[part 1 of 2: package /ComponentTypes]
AUTOSAR XML (schema 00050)
package /ComponentTypes
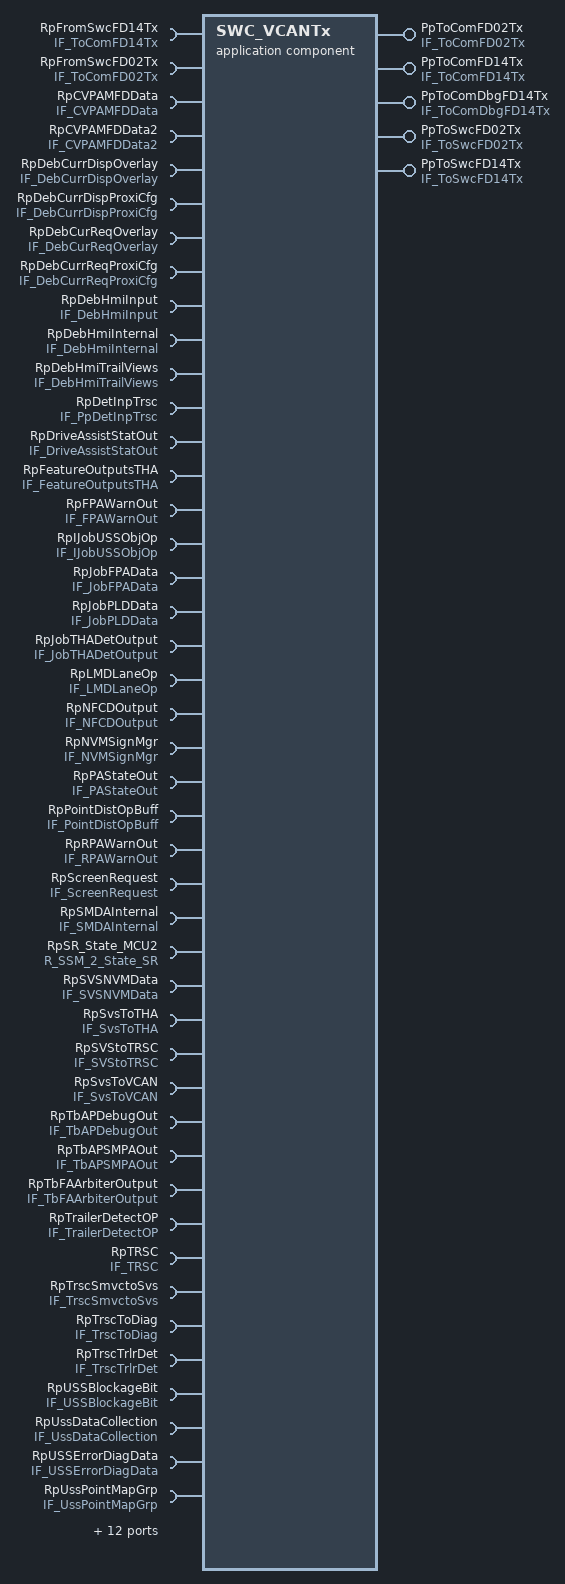
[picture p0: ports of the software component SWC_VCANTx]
  application sw component type SWC_VCANTx
    provide port PpToComFD02Tx: provided-interface=IF_ToComFD02Tx
      provided-com-specs:
        data-element=CurrentCanNMState_FD02_PAM, init-value=0
        data-element=CurrentFailSts_FD02_PAM, init-value=0
        data-element=DES_FD02_PAM, init-value=0
        data-element=Digit_{01..11}_PAM, init-value=0
        data-element=EOL_FD02_PAM, init-value=0
        data-element=GenericFailSts_FD02_PAM, init-value=0
        {data-element=N_PDU, init-value=[rule-based-values={rule=FILL_UNTIL_END, rule-arguments=0}]}
        data-element=PreviousCanNMState_FD02_PAM, init-value=0
        {data-element=StayActiveSource_FD02_PAM, init-value=[rule-based-values={rule=FILL_UNTIL_END, rule-arguments=0}]}
        data-element=THA_EPB_Req, init-value=0
        data-element=THA_Speed_Limit, init-value=0
        data-element=THA_SpeedLimit_Req, init-value=0
        data-element=THA_STAT, init-value=0
        data-element=THA_SteeringDamping, init-value=78.125
        data-element=THA_SteeringTorqueInfo, init-value=0
        data-element=THA_SteeringTorqueReq, init-value=0
        data-element=Trailer_Angle, init-value=0
        data-element=Trailer_Angle_Sign, init-value=0
        data-element=Trailer_Calibration, init-value=0
        data-element=TrlrHitchLight_Cntrl, init-value=0
        data-element=TRSC_PopupDisp_Info, init-value=0
        data-element=TRSC_SpeedLimit_Req, init-value=0
        data-element=TRSC_STAT, init-value=1
        data-element=TRSC_SteeringDamping, init-value=100
        data-element=TRSC_SteeringTorqueInfo, init-value=0
        data-element=TRSC_SteeringTorqueReq, init-value=0
        data-element=TRSC_VehicleStop_Req, init-value=3
        data-element=TRSCMoreCamRQSts, init-value=0
        data-element=WakeupSource_FD02_PAM, init-value=0
        data-element=TRSC_PopupDisp_Info2, init-value=0
    provide port PpToComFD14Tx: provided-interface=IF_ToComFD14Tx
      provided-com-specs:
        data-element=FD14_THA_EPB_Req, init-value=0
        data-element=FD14_THA_Speed_Limit, init-value=0
        data-element=FD14_THA_SpeedLimit_Req, init-value=0
        data-element=FD14_THA_STAT, init-value=0
        data-element=FD14_THA_SteeringDamping, init-value=100
        data-element=FD14_THA_SteeringTorqueInfo, init-value=1024
        data-element=FD14_THA_SteeringTorqueReq, init-value=0
        data-element=FD14_TRSC_SpeedLimit_Req, init-value=0
        data-element=FD14_TRSC_STAT, init-value=1
        data-element=FD14_TRSC_SteeringDamping, init-value=100
        data-element=FD14_TRSC_SteeringTorqueInfo, init-value=1024
        data-element=FD14_TRSC_SteeringTorqueReq, init-value=0
        data-element=FD14_TRSC_VehicleStop_Req, init-value=3
    require port RpFromSwcFD14Tx: required-interface=IF_ToComFD14Tx
      required-com-specs:
        data-element=FD14_THA_EPB_Req, filter=data-filter-type=ALWAYS, init-value=0
        data-element=FD14_THA_Speed_Limit, filter=data-filter-type=ALWAYS, init-value=0
        data-element=FD14_THA_SpeedLimit_Req, filter=data-filter-type=ALWAYS, init-value=0
        data-element=FD14_THA_STAT, filter=data-filter-type=ALWAYS, init-value=0
        data-element=FD14_THA_SteeringDamping, filter=data-filter-type=ALWAYS, init-value=100
        data-element=FD14_THA_SteeringTorqueInfo, filter=data-filter-type=ALWAYS, init-value=1024
        data-element=FD14_THA_SteeringTorqueReq, filter=data-filter-type=ALWAYS, init-value=0
        data-element=FD14_TRSC_SpeedLimit_Req, filter=data-filter-type=ALWAYS, init-value=0
        data-element=FD14_TRSC_STAT, filter=data-filter-type=ALWAYS, init-value=1
        data-element=FD14_TRSC_SteeringDamping, filter=data-filter-type=ALWAYS, init-value=100
        data-element=FD14_TRSC_SteeringTorqueInfo, filter=data-filter-type=ALWAYS, init-value=1024
        data-element=FD14_TRSC_SteeringTorqueReq, filter=data-filter-type=ALWAYS, init-value=0
        data-element=FD14_TRSC_VehicleStop_Req, filter=data-filter-type=ALWAYS, init-value=3
    provide port PpToComDbgFD14Tx: provided-interface=IF_ToComDbgFD14Tx
      provided-com-specs:
        data-element=FD14_MeTRSC_cnt_TRSCAliveCounter, init-value=0
        data-element=FD14_MeTRSC_deg_TADAngleSMVC, init-value=0
        data-element=FD14_MeTRSC_e_TrlrCalInfoSMVC, init-value=0
        data-element=FD14_MeTRSC_s_TRSCPeriodicity, init-value=0
        data-element=FD14_MeTRSC_s_TRSCTimeTaken, init-value=0
        data-element=FD14_ReservedSignal1, init-value=0
        data-element=FD14_ReservedSignal2, init-value=0
        data-element=FD14_ReservedTRSCSig1, init-value=0
        data-element=FD14_ReservedTRSCSig2, init-value=0
        data-element=FD14_averageIllumination, init-value=0
        data-element=FD14_CsmLocalErrOrEventId, init-value=0
        data-element=FD14_CsmLocalErrOrEventState, init-value=7
        data-element=FD14_CsmLocalModuleId, init-value=15
        data-element=FD14_CsmLocalModuleInstanceId, init-value=0
        data-element=FD14_CsmStateCurrent, init-value=15
        data-element=FD14_CsmStatePrevious, init-value=15
        data-element=FD14_hitchCalibrationAngle, init-value=0
        data-element=FD14_leftCalibrationAngle, init-value=0
        data-element=FD14_MeTRSC_b_OTBLReset, init-value=0
        data-element=FD14_MeTRSC_b_TBLComputationDone, init-value=0
        data-element=FD14_MeTRSC_deg_StrCMD, init-value=0
        data-element=FD14_rightCalibrationAngle, init-value=0
        data-element=FD14__JackKnifeAngle, init-value=0
        data-element=FD14_AOL_Blockage, init-value=0
        data-element=FD14_AOL_comm_Fault, init-value=0
        data-element=FD14_AOL_CommUnknown, init-value=0
        data-element=FD14_AOL_hardware_Fault, init-value=0
        data-element=FD14_AOL_MinDistance, init-value=0
        data-element=FD14_AOL_overTemp_Fault, init-value=0
        data-element=FD14_AOR_Blockage, init-value=0
        data-element=FD14_AOR_comm_Fault, init-value=0
        data-element=FD14_AOR_CommUnknown, init-value=0
        data-element=FD14_AOR_hardware_Fault, init-value=0
        data-element=FD14_AOR_MinDistance, init-value=0
        data-element=FD14_AOR_overTemp_Fault, init-value=0
        data-element=FD14_AutoParkInitializedStatus_b, init-value=0
        data-element=FD14_AuxCamButton1NoSelect_b, init-value=0
        data-element=FD14_AuxCamButton1Select_b, init-value=0
        data-element=FD14_AuxCamButton2NoSelect_b, init-value=0
        data-element=FD14_AuxCamButton2Select_b, init-value=0
        data-element=FD14_BackCam_NA_b, init-value=0
        data-element=FD14_BackDoorOpen_Icon_b, init-value=0
        data-element=FD14_BackupRearCamButtonNoSelect_b, init-value=0
        data-element=FD14_BackupRearCamButtonSelect_b, init-value=0
        data-element=FD14_BOL_Blockage, init-value=0
        data-element=FD14_BOL_comm_Fault, init-value=0
        data-element=FD14_BOL_CommUnknown, init-value=0
        data-element=FD14_BOL_hardware_Fault, init-value=0
        data-element=FD14_BOL_MinDistance, init-value=0
        data-element=FD14_BOL_overTemp_Fault, init-value=0
        data-element=FD14_BOR_Blockage, init-value=0
        data-element=FD14_BOR_comm_Fault, init-value=0
        data-element=FD14_BOR_CommUnknown, init-value=0
        data-element=FD14_BOR_hardware_Fault, init-value=0
        data-element=FD14_BOR_MinDistance, init-value=0
        data-element=FD14_BOR_overTemp_Fault, init-value=0
        data-element=FD14_BumberStatus_Front, init-value=0
        data-element=FD14_BumberStatus_Left_Side, init-value=0
        data-element=FD14_BumberStatus_Rear, init-value=0
        data-element=FD14_BumberStatus_Right_Side, init-value=0
        data-element=FD14_calibrationCompleted, init-value=0
        data-element=FD14_calibrationSubState, init-value=0
        data-element=FD14_CalibStatus_STM_Current_Front, init-value=0
        data-element=FD14_CalibStatus_STM_Current_Left, init-value=0
        data-element=FD14_CalibStatus_STM_Current_Rear, init-value=0
        data-element=FD14_CalibStatus_STM_Current_Right, init-value=0
        data-element=FD14_CalibStatus_STM_EOL_Front, init-value=0
        data-element=FD14_CalibStatus_STM_EOL_Left, init-value=0
        data-element=FD14_CalibStatus_STM_EOL_Rear, init-value=0
        data-element=FD14_CalibStatus_STM_EOL_Right, init-value=0
        data-element=FD14_CalibStatus_STM_OC_Front, init-value=0
        data-element=FD14_CalibStatus_STM_OC_Left, init-value=0
        data-element=FD14_CalibStatus_STM_OC_Rear, init-value=0
        data-element=FD14_CalibStatus_STM_OC_Right, init-value=0
        data-element=FD14_CalibStatus_STM_SC_Front, init-value=0
        data-element=FD14_CalibStatus_STM_SC_Left, init-value=0
        data-element=FD14_CalibStatus_STM_SC_Rear, init-value=0
        data-element=FD14_CalibStatus_STM_SC_Right, init-value=0
        data-element=FD14_CAM_NA_Bitfield_u8, init-value=0
        data-element=FD14_CameraDisplaySts2_e, init-value=0
        data-element=FD14_cntrCvpamFdData1_u16, init-value=0
        data-element=FD14_crcCvpamFdData1_u8, init-value=0
        data-element=FD14_Curr_DisplayedViewByAcore_e, init-value=0
        data-element=FD14_Curr_RequestedViewByHmiM_e, init-value=0
        data-element=FD14_Curr_SystemState_e, init-value=0
        data-element=FD14_Curr_TRG_Stat, init-value=0
        data-element=FD14_Current_Firing_Sequence, init-value=0
        data-element=FD14_CurrentTrailer_ID, init-value=6
        data-element=FD14_curState, init-value=0
        data-element=FD14_Debug_Signal_{1..8}, init-value=0
        data-element=FD14_DynOvl_Error_e, init-value=0
        data-element=FD14_EOL_ModuleState_STM_Front, init-value=0
        data-element=FD14_EOL_ModuleState_STM_Left, init-value=0
        data-element=FD14_EOL_ModuleState_STM_Rear, init-value=0
        data-element=FD14_EOL_ModuleState_STM_Right, init-value=0
        data-element=FD14_Err_Code_EOL_Front, init-value=0
        data-element=FD14_Err_Code_EOL_Left, init-value=0
        data-element=FD14_Err_Code_EOL_Rear, init-value=0
        data-element=FD14_Err_Code_EOL_Rear_Copy_1, init-value=0
        data-element=FD14_Err_Code_OC_Front, init-value=0
        data-element=FD14_Err_Code_OC_Left, init-value=0
        data-element=FD14_Err_Code_OC_Rear, init-value=0
        data-element=FD14_Err_Code_OC_Right, init-value=0
        data-element=FD14_Err_Code_SC_Front, init-value=0
        data-element=FD14_Err_Code_SC_Left, init-value=0
        data-element=FD14_Err_Code_SC_Rear, init-value=0
        data-element=FD14_Err_Code_SC_Right, init-value=0
        data-element=FD14_FFCV_BTN_PRESSED_b, init-value=0
        data-element=FD14_FIL_Blockage, init-value=0
        data-element=FD14_FIL_comm_Fault, init-value=0
        data-element=FD14_FIL_CommUnknown, init-value=0
        data-element=FD14_FIL_hardware_Fault, init-value=0
        data-element=FD14_FIL_MinDistance, init-value=0
        data-element=FD14_FIL_overTemp_Fault, init-value=0
        data-element=FD14_FIR_Blockage, init-value=0
        data-element=FD14_FIR_comm_Fault, init-value=0
        data-element=FD14_FIR_CommUnknown, init-value=0
        data-element=FD14_FIR_hardware_Fault, init-value=0
        data-element=FD14_FIR_MinDistance, init-value=0
        data-element=FD14_FIR_overTemp_Fault, init-value=0
        data-element=FD14_Firing_Mode_Seq, init-value=0
        data-element=FD14_Firing_Sensor, init-value=0
        data-element=FD14_Firing_Sensor_Info_F, init-value=0
        data-element=FD14_Firing_Sensor_Info_R, init-value=0
        data-element=FD14_FiringMode_TimeStamp, init-value=0
        data-element=FD14_FiringSnr_TimeStamp, init-value=0
        data-element=FD14_FOL_Blockage, init-value=0
        data-element=FD14_FOL_comm_Fault, init-value=0
        data-element=FD14_FOL_CommUnknown, init-value=0
        data-element=FD14_FOL_hardware_Fault, init-value=0
        data-element=FD14_FOL_MinDistance, init-value=0
        data-element=FD14_FOL_overTemp_Fault, init-value=0
        data-element=FD14_FOR_Blockage, init-value=0
        data-element=FD14_FOR_comm_Fault, init-value=0
        data-element=FD14_FOR_CommUnknown, init-value=0
        data-element=FD14_FOR_hardware_Fault, init-value=0
        data-element=FD14_FOR_MinDistance, init-value=0
        data-element=FD14_FOR_overTemp_Fault, init-value=0
        data-element=FD14_Frame_Index_Lanes__1, init-value=0
        data-element=FD14_Frameset1AndTopFrontText_b, init-value=0
        data-element=FD14_Frameset1AndTopRearText_b, init-value=0
        data-element=FD14_Frameset2AndFrontCrossText_b, init-value=0
        data-element=FD14_Frameset2AndRearCrossText_b, init-value=0
        data-element=FD14_FRONT_CROSS_BTN_PRESSED_b, init-value=0
        data-element=FD14_FRONT_TOP_BTN_PRESSED_b, init-value=0
        data-element=FD14_FrontCam_NA_b, init-value=0
        data-element=FD14_FrontCrossButtonNoSelect_b, init-value=0
        data-element=FD14_FrontCrossButtonSelect_b, init-value=0
        data-element=FD14_FrontFaceCamButtonNoSelect_b, init-value=0
        data-element=FD14_FrontFaceCamButtonSelect_b, init-value=0
        data-element=FD14_FrontSensorDetHealth_e, init-value=0
        data-element=FD14_FrontTireTracks_b, init-value=0
        data-element=FD14_FrontViewDynamics_b, init-value=0
        data-element=FD14_FSL_Blockage, init-value=0
        data-element=FD14_FSL_comm_Fault, init-value=0
        data-element=FD14_FSL_CommUnknown, init-value=0
        data-element=FD14_FSL_hardware_Fault, init-value=0
        data-element=FD14_FSL_MinDistance, init-value=0
        data-element=FD14_FSL_overTemp_Fault, init-value=0
        data-element=FD14_FSR_Blockage, init-value=0
        data-element=FD14_FSR_comm_Fault, init-value=0
        data-element=FD14_FSR_CommUnknown, init-value=0
        data-element=FD14_FSR_hardware_Fault, init-value=0
        data-element=FD14_FSR_MinDistance, init-value=0
        data-element=FD14_FSR_overTemp_Fault, init-value=0
        data-element=FD14_GW_C_I6_timeout_b, init-value=1
        data-element=FD14_hitchLength, init-value=100000
        data-element=FD14_IeAP_b_MnvPosOk, init-value=0
        data-element=FD14_IeAP_cm_FrntCenterMinXDist, init-value=0
        data-element=FD14_IeAP_cm_FrntCenterMinXDist_KPI, init-value=0
        data-element=FD14_IeAP_cm_FrntLeftMinXDist, init-value=0
        data-element=FD14_IeAP_cm_FrntLeftMinXDist_KPI, init-value=0
        data-element=FD14_IeAP_cm_FrntRightMinXDist, init-value=0
        data-element=FD14_IeAP_cm_FrntRightMinXDist_KPI, init-value=0
        data-element=FD14_IeAP_cm_RearCenterMinXDist, init-value=0
        data-element=FD14_IeAP_cm_RearCenterMinXDist_KPI, init-value=0
        data-element=FD14_IeAP_cm_RearLeftMinXDist, init-value=0
        data-element=FD14_IeAP_cm_RearLeftMinXDist_KPI, init-value=0
        data-element=FD14_IeAP_cm_RearRightMinXDist, init-value=0
        data-element=FD14_IeAP_cm_RearRightMinXDist_KPI, init-value=0
        data-element=FD14_IeAP_cnt_CurrentVehSweep, init-value=0
        data-element=FD14_IeAP_e_AbortCon, init-value=0
        data-element=FD14_IeAP_e_AutoParkStatus, init-value=0
        data-element=FD14_IeAutoPark_e_AlgoState, init-value=0
        data-element=FD14_IeLMD_e_CameraStatus, init-value=0
        data-element=FD14_IeTHA_b_ChimeActvLhf, init-value=0
        data-element=FD14_IeTHA_b_ChimeActvRhf, init-value=0
        data-element=FD14_IeTHA_e_PamChimeTyp, init-value=0
        data-element=FD14_IeTHA_e_PamVol, init-value=0
        data-element=FD14_IeTRSC_cnt_KnobPos, init-value=0
        data-element=FD14_IeTRSC_cnt_TrlrCalibFailCnt, init-value=0
        data-element=FD14_IeTRSC_cnt_TrlrCalibFailCntCurr, init-value=0
        data-element=FD14_IeTRSC_cnt_TrlrCalibPassCnt, init-value=0
        data-element=FD14_IeTRSC_cnt_TrlrCalibPassCntCurr, init-value=0
        data-element=FD14_IeTRSC_deg_FrntWhlAng, init-value=0
        data-element=FD14_IeTRSC_deg_JackknifeThrAngle, init-value=0
        data-element=FD14_IeTRSC_deg_TADAngle, init-value=0
        data-element=FD14_IeTRSC_deg_TrlrAngKnob, init-value=0
        data-element=FD14_IeTRSC_e_CamBlockSts, init-value=0
        data-element=FD14_IeTRSC_e_GearShiftSts, init-value=0
        data-element=FD14_IeTRSC_e_TrailerID, init-value=0
        data-element=FD14_IeTRSC_e_TrlrAngGrapOverSts, init-value=0
        data-element=FD14_IeTRSC_e_TrlrCalibFailReas, init-value=0
        data-element=FD14_IeTRSC_e_TrlrCalibManState, init-value=0
        data-element=FD14_IeTRSC_e_TrlrCalibSts, init-value=0
        data-element=FD14_IeTRSC_e_TrlrPrsntFailReas, init-value=0
        data-element=FD14_IeTRSC_e_TrlrPrsntSts, init-value=0
        data-element=FD14_IeTRSC_e_TrlrRecogInfo, init-value=0
        data-element=FD14_IeTRSC_e_TRSCAbortReas, init-value=0
        data-element=FD14_IeTRSC_e_TRSCUnavailReas, init-value=0
        data-element=FD14_IeTRSC_e_TRSKMBtnSts, init-value=0
        data-element=FD14_IeTRSC_e_TRSKMCenBtnSts, init-value=0
        data-element=FD14_IeTRSC_e_TRSKMSts, init-value=0
        data-element=FD14_IeTRSC_kph_VehSpeedVSOSig, init-value=0
        data-element=FD14_IeTRSC_m_TrlrWhlBaseEff, init-value=0
        data-element=FD14_IeTRSC_M_TRSCStrTrq, init-value=0
        data-element=FD14_IeTRSC_pct_TrlrDetConf, init-value=0
        data-element=FD14_IeTRSC_pct_TrlrRecogConf, init-value=0
        data-element=FD14_IeTRSC_pct_TrlrTrackConf, init-value=0
        data-element=FD14_IeVBII_nfcd_MinDisToCollisionObj, init-value=0
        data-element=FD14_ignitionStatus_e, init-value=0
        data-element=FD14_IgnoredFeatures_Front_u32, init-value=0
        data-element=FD14_IgnoredFeatures_Left_u32, init-value=0
        data-element=FD14_IgnoredFeatures_Rear_u32, init-value=0
        data-element=FD14_IgnoredFeatures_Right_u32, init-value=0
        data-element=FD14_IgnoreVehicleOffSpeed, init-value=0
        data-element=FD14_ImageDefeat_Error_e, init-value=0
        data-element=FD14_InvalidFeatures_Front_u32, init-value=0
        data-element=FD14_InvalidFeatures_Left_u32, init-value=0
        data-element=FD14_InvalidFeatures_Rear_u32, init-value=0
        data-element=FD14_InvalidFeatures_Right_u32, init-value=0
        data-element=FD14_IsBackSftbtnSel, init-value=0
        data-element=FD14_IsExitSftBtnSel, init-value=0
        data-element=FD14_IsParkSftBtnSel, init-value=0
        data-element=FD14_isPLDInitSuccess_b, init-value=0
        data-element=FD14_IsSlotSel, init-value=0
        data-element=FD14_isUSSInitSuccess_b, init-value=0
        data-element=FD14_ItbmTrailerStatus, init-value=0
        data-element=FD14_JackknifeAngle, init-value=0
        data-element=FD14_JackknifeThrAngle, init-value=0
        data-element=FD14_KnobAngle, init-value=0
        data-element=FD14_LanguageSelection_u8, init-value=0
        data-element=FD14_LastViewBeforeTestPattern_e, init-value=0
        data-element=FD14_LeftCam_NA_b, init-value=0
        data-element=FD14_LeftDoorFrontClose_Icon_b, init-value=0
        data-element=FD14_LeftDoorFrontOpen_Icon_b, init-value=0
        data-element=FD14_LeftDoorRearClose_Icon_b, init-value=0
        data-element=FD14_LeftDoorRearOpen_Icon_b, init-value=0
        data-element=FD14_leLMD_e_HealthStatus, init-value=0
        data-element=FD14_LMD_e_Line_{1..4}_Type, init-value=0
        data-element=FD14_LMD_e_Segment_{1..8}_ID, init-value=0
        data-element=FD14_LMD_m_Line_1_End_Range, init-value=0
        data-element=FD14_LMD_m_Line_1_Offset, init-value=0
        data-element=FD14_LMD_m_Line_1_Start_Range, init-value=0
        data-element=FD14_LMD_m_Line_2_End_Range, init-value=0
        data-element=FD14_LMD_m_Line_2_Offset, init-value=0
        data-element=FD14_LMD_m_Line_2_Start_Range, init-value=0
        data-element=FD14_LMD_m_Line_3_End_Range, init-value=0
        data-element=FD14_LMD_m_Line_3_Offset, init-value=0
        data-element=FD14_LMD_m_Line_3_Start_Range, init-value=0
        data-element=FD14_LMD_m_Line_4_End_Range, init-value=0
        data-element=FD14_LMD_m_Line_4_Offset, init-value=0
        data-element=FD14_LMD_m_Line_4_Start_Range, init-value=0
        data-element=FD14_LMD_m_Segment_1_X1, init-value=0
        data-element=FD14_LMD_m_Segment_1_X2, init-value=0
        data-element=FD14_LMD_m_Segment_1_Y1, init-value=0
        data-element=FD14_LMD_m_Segment_1_Y2, init-value=0
        data-element=FD14_LMD_m_Segment_2_X1, init-value=0
        data-element=FD14_LMD_m_Segment_2_X2, init-value=0
        data-element=FD14_LMD_m_Segment_2_Y1, init-value=0
        data-element=FD14_LMD_m_Segment_2_Y2, init-value=0
        data-element=FD14_LMD_m_Segment_3_X1, init-value=0
        data-element=FD14_LMD_m_Segment_3_X2, init-value=0
        data-element=FD14_LMD_m_Segment_3_Y1, init-value=0
        data-element=FD14_LMD_m_Segment_3_Y2, init-value=0
        data-element=FD14_LMD_m_Segment_4_X1, init-value=0
        data-element=FD14_LMD_m_Segment_4_X2, init-value=0
        data-element=FD14_LMD_m_Segment_4_Y1, init-value=0
        data-element=FD14_LMD_m_Segment_4_Y2, init-value=0
        data-element=FD14_LMD_m_Segment_5_X1, init-value=0
        data-element=FD14_LMD_m_Segment_5_X2, init-value=0
        data-element=FD14_LMD_m_Segment_5_Y1, init-value=0
        data-element=FD14_LMD_m_Segment_5_Y2, init-value=0
        data-element=FD14_LMD_m_Segment_6_X1, init-value=0
        data-element=FD14_LMD_m_Segment_6_X2, init-value=0
        data-element=FD14_LMD_m_Segment_6_Y1, init-value=0
        data-element=FD14_LMD_m_Segment_6_Y2, init-value=0
        data-element=FD14_LMD_m_Segment_7_X1, init-value=0
        data-element=FD14_LMD_m_Segment_7_X2, init-value=0
        data-element=FD14_LMD_m_Segment_7_Y1, init-value=0
        data-element=FD14_LMD_m_Segment_7_Y2, init-value=0
        data-element=FD14_LMD_m_Segment_8_X1, init-value=0
        data-element=FD14_LMD_m_Segment_8_X2, init-value=0
        data-element=FD14_LMD_m_Segment_8_Y1, init-value=0
        data-element=FD14_LMD_m_Segment_8_Y2, init-value=0
        data-element=FD14_LMD_pct_Line_{1..4}_Confidence, init-value=0
        data-element=FD14_LMD_pct_Segment_{1..8}_Confidence, init-value=0
        data-element=FD14_LMD_px_Line_{1..4}_Curvature, init-value=0
        data-element=FD14_LMD_rad_Line_{1..4}_Heading, init-value=0
        {data-element=FD14_Log_Sensor_Temperature, init-value=[rule-based-values={rule=FILL_UNTIL_END, rule-arguments=0}]}
        {data-element=FD14_Log_SnrMeasData_{1..7}, init-value=[rule-based-values={rule=FILL_UNTIL_END, rule-arguments=0}]}
        data-element=FD14_lrwsST_e, init-value=0
        data-element=FD14_M_BURV_Memory_e, init-value=0
        data-element=FD14_M_CONFIRM_BTN_PRESSED_b, init-value=0
        data-element=FD14_M_Cplr_Htch_Distance, init-value=0
        data-element=FD14_M_CPLR_POS_X_u, init-value=0
        data-element=FD14_M_CPLR_POS_Y_u, init-value=0
        data-element=FD14_M_Current_THA_State_On_Screen, init-value=0
        data-element=FD14_M_Current_THA_State_On_Zync, init-value=0
        data-element=FD14_M_FFClatch_e, init-value=0
        data-element=FD14_m_FPAInfoToPLDSlotID, init-value=0
        data-element=FD14_m_FPAInfoToUSSOMSlotID, init-value=0
        data-element=FD14_m_FpaInfoToVCParkOutStyle, init-value=0
        data-element=FD14_m_FPAToNVMParkInStyle, init-value=0
        data-element=FD14_m_FPAToNVMReadNVMParam_b, init-value=0
        data-element=FD14_m_FPAToNVMWriteNVMParam_b, init-value=0
        data-element=FD14_M_Maneuver_Initial_Run, init-value=0
        data-element=FD14_M_Progress_Bar_Distance, init-value=0
        data-element=FD14_M_Progress_Bar_Percentage, init-value=0
        data-element=FD14_m_QM_FID_TRSC_ASCMDef, init-value=0
        data-element=FD14_m_QM_FID_TRSC_CAM_CAL_ABORT, init-value=0
        data-element=FD14_m_QM_FID_TRSC_DISABLED, init-value=0
        data-element=FD14_m_QM_FID_TRSC_LIMITED_DefView, init-value=0
        data-element=FD14_m_QM_FID_TRSC_LIMITED_View, init-value=0
        data-element=FD14_M_Requested_THA_State, init-value=0
        data-element=FD14_M_START_BTN_PRESSED_b, init-value=0
        data-element=FD14_M_THA_SFT_BTN_PRESSED_b, init-value=0
        data-element=FD14_M_VIEW_SCRN_TCH_STS_b, init-value=0
        data-element=FD14_M_VIEW_ZOOM_STS_b, init-value=0
        data-element=FD14_MaAP_m_ParkSpot1FrntStreetX, init-value=0
        data-element=FD14_MaAP_m_ParkSpot1FrntStreetY, init-value=0
        data-element=FD14_MaAP_m_ParkSpot2FrntBorderX, init-value=0
        data-element=FD14_MaAP_m_ParkSpot2FrntBorderY, init-value=0
        data-element=FD14_MaAP_m_ParkSpot3RearBorderX, init-value=0
        data-element=FD14_MaAP_m_ParkSpot3RearBorderY, init-value=0
        data-element=FD14_MaAP_m_ParkSpot4RearStreetX, init-value=0
        data-element=FD14_MaAP_m_ParkSpot4RearStreetY, init-value=0
        {data-element=FD14_macCvpamFdData1_u64, init-value=[rule-based-values={rule=FILL_UNTIL_END, rule-arguments=0}]}
        data-element=FD14_MAGNIFIER_BTN_PRESSED_b, init-value=0
        data-element=FD14_MaxTadAngle, init-value=0
        data-element=FD14_MeAP_a_BrkCmd, init-value=0
        data-element=FD14_MeAP_a_ThrtlCmd, init-value=0
        data-element=FD14_MeAP_b_APInitSts, init-value=0
        data-element=FD14_MeAP_b_BSMHandshakeActv, init-value=0
        data-element=FD14_MeAP_b_BSMInterfaceTimeout, init-value=0
        data-element=FD14_MeAP_b_CamHandshakeTimeout, init-value=0
        data-element=FD14_MeAP_b_DriverOverride, init-value=0
        data-element=FD14_MeAP_b_EPSInterfaceTimeout, init-value=0
        data-element=FD14_MeAP_b_FeatureEnbl, init-value=0
        data-element=FD14_MeAP_b_FPADisable, init-value=0
        data-element=FD14_MeAP_b_FPAStatus, init-value=0
        data-element=FD14_MeAP_b_FPAVolDefMed, init-value=0
        data-element=FD14_MeAP_b_GearShiftWaitTimeout, init-value=0
        data-element=FD14_MeAP_b_ManeuverAbort, init-value=0
        data-element=FD14_MeAP_b_ManeuverSuccess, init-value=0
        data-element=FD14_MeAP_b_ObjInPathTimeout, init-value=0
        data-element=FD14_MeAP_b_PARBActv4LOW, init-value=0
        data-element=FD14_MeAP_b_PARBActvTrlr, init-value=0
        data-element=FD14_MeAP_b_PARBDisable, init-value=0
        data-element=FD14_MeAP_b_PausedPressBtnTimeout, init-value=0
        data-element=FD14_MeAP_b_PAVolDefMed, init-value=0
        data-element=FD14_MeAP_b_PosMet, init-value=0
        data-element=FD14_MeAP_b_PPPAActv4LOW, init-value=0
        data-element=FD14_MeAP_b_PPPAActvTrlr, init-value=0
        data-element=FD14_MeAP_b_PPPADefEng, init-value=0
        data-element=FD14_MeAP_b_PPPADisable, init-value=0
        data-element=FD14_MeAP_b_RPAActvTrlr, init-value=0
        data-element=FD14_MeAP_b_RPADisable, init-value=0
        data-element=FD14_MeAP_b_RPAStatus, init-value=0
        data-element=FD14_MeAP_b_RPAVolDefMed, init-value=0
        data-element=FD14_MeAP_b_RPAwithBrkStatus, init-value=0
        data-element=FD14_MeAP_b_SeekSpdExceedTimeout, init-value=0
        data-element=FD14_MeAP_b_StandStill, init-value=0
        data-element=FD14_MeAP_b_SteerActionReq, init-value=0
        data-element=FD14_MeAP_b_VCOpPaused, init-value=0
        data-element=FD14_MeAP_b_VehCndSts, init-value=0
        data-element=FD14_MeAP_cm_FrntCenterMinXDist, init-value=0
        data-element=FD14_MeAP_cm_FrntLeftMinXDist, init-value=0
        data-element=FD14_MeAP_cm_FrntRightMinXDist, init-value=0
        data-element=FD14_MeAP_cm_RearCenterMinXDist, init-value=0
        data-element=FD14_MeAP_cm_RearLeftMinXDist, init-value=0
        data-element=FD14_MeAP_cm_RearRightMinXDist, init-value=0
        data-element=FD14_MeAP_cnt_StateDebugVar, init-value=0
        data-element=FD14_MeAP_cnt_TransDebugVar, init-value=0
        data-element=FD14_MeAP_cnt_TransDebugVar_Copy_1, init-value=0
        data-element=FD14_MeAP_deg_StrCmd, init-value=0
        data-element=FD14_MeAP_e_Park_state, init-value=0
        data-element=FD14_MeAP_e_ParkAssistStatus, init-value=0
        data-element=FD14_MeAP_e_PP_state, init-value=0
        data-element=FD14_MePRX_b_AuxTrlrCam, init-value=1
        data-element=FD14_MePRX_b_CanNode27, init-value=1
        data-element=FD14_MePRX_b_CANNode95, init-value=1
        data-element=FD14_MePRX_b_FrwFacingCam, init-value=1
        data-element=FD14_MePRX_b_SurroundViewCamera, init-value=1
        data-element=FD14_MePRX_b_TRGPresence, init-value=1
        data-element=FD14_MePRX_b_TRSCPresence, init-value=1
        data-element=FD14_MePRX_e_AutonomyLvl, init-value=0
        data-element=FD14_MePRX_e_MirrorType, init-value=0
        data-element=FD14_MePRX_e_PAMTunSet, init-value=0
        data-element=FD14_MePRX_e_RadDispType, init-value=0
        data-element=FD14_MePRX_e_SteerRatRackPinionType, init-value=0
        data-element=FD14_MePRX_e_VariantID, init-value=0
        data-element=FD14_MePRX_e_VehLineCfg, init-value=0
        data-element=FD14_MePRX_e_Wheelbase, init-value=0
        data-element=FD14_MeSVS_b_MoreCamReqSts, init-value=0
        data-element=FD14_MeSVS_e_DispView2Info, init-value=0
        data-element=FD14_MeTHA_b_EnblRearParkAsstTrg, init-value=0
        data-element=FD14_MeTHA_b_THAAbortStatus, init-value=0
        data-element=FD14_MeTHA_b_TrlrCplrStatus, init-value=0
        data-element=FD14_MeTHA_b_UsrCplrSelCnfm, init-value=0
        data-element=FD14_MeTHA_b_UsrHitchCnfm, init-value=0
        data-element=FD14_MeTHA_deg_CplrAng, init-value=0
        data-element=FD14_MeTHA_deg_RoadWhlAng, init-value=0
        data-element=FD14_MeTHA_e_CplrDetctStatus, init-value=0
        data-element=FD14_MeTHA_e_HitchDetctStatus, init-value=0
        data-element=FD14_MeTHA_e_RearBrkSupprInfo, init-value=0
        data-element=FD14_MeTHA_e_ScreenRequest, init-value=0
        data-element=FD14_MeTHA_e_THAStateInfo, init-value=0
        data-element=FD14_MeTHA_pct_CplrDetConf, init-value=0
        data-element=FD14_MeTHA_pct_CplrTrckConf, init-value=0
        data-element=FD14_MeTHA_px_CplrPntX, init-value=327
        data-element=FD14_MeTHA_px_CplrPntY, init-value=298
        data-element=FD14_MeTHA_px_HitchCplrPixDiffLat, init-value=0
        data-element=FD14_MeTHA_px_HitchCplrPixDiffLong, init-value=0
        data-element=FD14_MeTHA_px_HitchPntX, init-value=327
        data-element=FD14_MeTHA_px_HitchPntY, init-value=298
        data-element=FD14_MeTRSC_b_MoreCamSoftButtEnbl, init-value=0
        data-element=FD14_MeTRSC_b_OBTLRecalibrate, init-value=0
        data-element=FD14_MeTRSC_b_TrlrCalibDelayInfo, init-value=0
        data-element=FD14_MeTRSC_b_TrlrCalibPopInfo, init-value=1
        data-element=FD14_MeTRSC_b_TrlrRevSteeringStsInfo, init-value=0
        data-element=FD14_MeTRSC_b_TRSCSwitchPressed, init-value=0
        data-element=FD14_MeTRSC_cnt_TrlrCalibFailCntInfo, init-value=0
        data-element=FD14_MeTRSC_deg_DetJackKnifeAngle, init-value=5300
        data-element=FD14_MeTRSC_deg_DetJackknifeThrAngle, init-value=5300
        data-element=FD14_MeTRSC_deg_JackKnifeAngle, init-value=5300
        data-element=FD14_MeTRSC_deg_JackknifeThrAngle, init-value=530
        data-element=FD14_MeTRSC_deg_KnobAngle, init-value=0
        data-element=FD14_MeTRSC_deg_MaxAllowedTADAngle, init-value=0
        data-element=FD14_MeTRSC_deg_TADAngle, init-value=0
        data-element=FD14_MeTRSC_deg_TADAngleRate, init-value=0
        data-element=FD14_MeTRSC_e_CalFail, init-value=0
        data-element=FD14_MeTRSC_e_TADCalibrationSubstate, init-value=0
        data-element=FD14_MeTRSC_e_TADState, init-value=0
        data-element=FD14_MeTRSC_e_TrailerID, init-value=6
        data-element=FD14_MeTRSC_e_TrlrAngSign, init-value=0
        data-element=FD14_MeTRSC_e_TrlrCalInfo, init-value=0
        data-element=FD14_MeTRSC_e_TrlrPrsntInfo, init-value=0
        data-element=FD14_MeTRSC_e_TrlrPrsntInfoCAN, init-value=0
        data-element=FD14_MeTRSC_e_TrlrRecogInfo, init-value=0
        data-element=FD14_MeTRSC_e_TRSCStat, init-value=0
        data-element=FD14_MeTRSC_e_TurnAroundSubState, init-value=0
        data-element=FD14_MeTRSC_m_DetTrailerBeamLen, init-value=100
        data-element=FD14_MeTRSC_m_HitchLength, init-value=100000
        data-element=FD14_MeTRSC_M_SteeringTorqInfo, init-value=0
        data-element=FD14_MeTRSC_m_TrailerBeamLen, init-value=100
        data-element=FD14_MinDistance_TimeStamp, init-value=0
        data-element=FD14_MoreCamsButton1NoSelect_b, init-value=0
        data-element=FD14_MoreCamsButton1Select_b, init-value=0
        data-element=FD14_MoreCamsButton2NoSelect_b, init-value=0
        data-element=FD14_MoreCamsButton2Select_b, init-value=0
        data-element=FD14_MoreCamsIconFullScreenNoSelect_b, init-value=0
        data-element=FD14_MOT_ClosestPntDist_0_{0..9}, init-value=0
        data-element=FD14_MOT_ClosestPntDist_1_{0..9}, init-value=0
        data-element=FD14_MOT_ObjectDimensions_0_{0..9}, init-value=0
        data-element=FD14_MOT_ObjectDimensions_1_{0..9}, init-value=0
        data-element=FD14_MOT_ObjValid_{0..9}, init-value=0
        data-element=FD14_MOT_ObjVelX_{0..9}, init-value=0
        data-element=FD14_MOT_ObjVelY_{0..9}, init-value=0
        data-element=FD14_msgcntrCvpamFdData1_u8, init-value=0
        data-element=FD14_NetCfg_TRSCM_e, init-value=0
        data-element=FD14_NFCD_DistanceToClosestPoint_0_{0..9}, init-value=0
        data-element=FD14_NFCD_DistanceToClosestPoint_1_{0..9}, init-value=0
        data-element=FD14_NFCD_ObjValid_{0..9}, init-value=0
        data-element=FD14_obj_Pos_Lat, init-value=0
        data-element=FD14_obj_Pos_Longi, init-value=0
        data-element=FD14_objConf_e, init-value=0
        data-element=FD14_OBTLRecalibrate, init-value=0
        data-element=FD14_OC_ModuleState_STM_Front, init-value=0
        data-element=FD14_OC_ModuleState_STM_Left, init-value=0
        data-element=FD14_OC_ModuleState_STM_Rear, init-value=0
        data-element=FD14_OC_ModuleState_STM_Right, init-value=0
        data-element=FD14_OFFRD_ABSNT_AUXCAM_BTN_PRESSED_b, init-value=0
        data-element=FD14_OFFRD_PRSNT_AUXCAM_BTN_PRESSED_b, init-value=0
        data-element=FD14_OFFROAD_ABSNT_MC_BTN_PRESSED_b, init-value=0
        data-element=FD14_OFFROAD_PRSNT_MC_BTN_PRESSED_b, init-value=0
        data-element=FD14_parkExtSideSel, init-value=0
        data-element=FD14_parkingDirection, init-value=0
        data-element=FD14_parkingSlotType, init-value=0
        data-element=FD14_PDC_FrontCenter_Red_b, init-value=0
        data-element=FD14_PDC_FrontCenter_Yellow_b, init-value=0
        data-element=FD14_PDC_FrontLeft_Red_b, init-value=0
        data-element=FD14_PDC_FrontLeft_Yellow_b, init-value=0
        data-element=FD14_PDC_FrontRight_Red_b, init-value=0
        data-element=FD14_PDC_FrontRight_Yellow_b, init-value=0
        data-element=FD14_PDC_RearCenter_Red_b, init-value=0
        data-element=FD14_PDC_RearCenter_Yellow_b, init-value=0
        data-element=FD14_PDC_RearLeft_Red_b, init-value=0
        data-element=FD14_PDC_RearLeft_Yellow_b, init-value=0
        data-element=FD14_PDC_RearRight_Red_b, init-value=0
        data-element=FD14_PDC_RearRight_Yellow_b, init-value=0
        data-element=FD14_perpParkDirectionSel, init-value=0
        data-element=FD14_Pitch_f32_Current_Rear, init-value=0
        data-element=FD14_Pitch_f32_Current_Right, init-value=0
        data-element=FD14_Pitch_f32_EOL_Front, init-value=0
        data-element=FD14_Pitch_f32_EOL_Left, init-value=0
        data-element=FD14_Pitch_f32_EOL_Rear, init-value=0
        data-element=FD14_Pitch_f32_EOL_Right, init-value=0
        data-element=FD14_Pitch_f32_OC_Front, init-value=0
        data-element=FD14_Pitch_f32_OC_Left, init-value=0
        data-element=FD14_Pitch_f32_OC_Rear, init-value=0
        data-element=FD14_Pitch_f32_OC_Right, init-value=0
        data-element=FD14_Pitch_f32_SC_Front, init-value=0
        data-element=FD14_Pitch_f32_SC_Left, init-value=0
        data-element=FD14_Pitch_f32_SC_Rear, init-value=0
        data-element=FD14_Pitch_f32_SC_Right, init-value=0
        {data-element=FD14_Pntdebugdata_{0..3}, init-value=[rule-based-values={rule=FILL_UNTIL_END, rule-arguments=0}]}
        data-element=FD14_Point_Map_Age_0, init-value=0
        data-element=FD14_Point_Map_Age_1, init-value=0
        data-element=FD14_Point_Map_Age_{10..19}, init-value=0
        data-element=FD14_Point_Map_Age_2, init-value=0
        data-element=FD14_Point_Map_Age_{20..29}, init-value=0
        data-element=FD14_Point_Map_Age_3, init-value=0
        data-element=FD14_Point_Map_Age_{30..39}, init-value=0
        data-element=FD14_Point_Map_Age_4, init-value=0
        data-element=FD14_Point_Map_Age_{40..49}, init-value=0
        data-element=FD14_Point_Map_Age_5, init-value=0
        data-element=FD14_Point_Map_Age_{50..59}, init-value=0
        data-element=FD14_Point_Map_Age_6, init-value=0
        data-element=FD14_Point_Map_Age_{60..69}, init-value=0
        data-element=FD14_Point_Map_Age_7, init-value=0
        data-element=FD14_Point_Map_Age_{70..79}, init-value=0
        data-element=FD14_Point_Map_Age_8, init-value=0
        data-element=FD14_Point_Map_Age_{80..89}, init-value=0
        data-element=FD14_Point_Map_Age_9, init-value=0
        data-element=FD14_Point_Map_Age_{90..95}, init-value=0
        data-element=FD14_Point_Map_Confidence_0, init-value=0
        data-element=FD14_Point_Map_Confidence_1, init-value=0
        data-element=FD14_Point_Map_Confidence_{10..19}, init-value=0
        data-element=FD14_Point_Map_Confidence_2, init-value=0
        data-element=FD14_Point_Map_Confidence_{20..29}, init-value=0
        data-element=FD14_Point_Map_Confidence_3, init-value=0
        data-element=FD14_Point_Map_Confidence_{30..39}, init-value=0
        data-element=FD14_Point_Map_Confidence_4, init-value=0
        data-element=FD14_Point_Map_Confidence_{40..49}, init-value=0
        data-element=FD14_Point_Map_Confidence_5, init-value=0
        data-element=FD14_Point_Map_Confidence_{50..59}, init-value=0
        data-element=FD14_Point_Map_Confidence_6, init-value=0
        data-element=FD14_Point_Map_Confidence_{60..69}, init-value=0
        data-element=FD14_Point_Map_Confidence_7, init-value=0
        data-element=FD14_Point_Map_Confidence_{70..79}, init-value=0
        data-element=FD14_Point_Map_Confidence_8, init-value=0
        data-element=FD14_Point_Map_Confidence_{80..89}, init-value=0
        data-element=FD14_Point_Map_Confidence_9, init-value=0
        data-element=FD14_Point_Map_Confidence_{90..95}, init-value=0
        data-element=FD14_Point_Map_Cruising_Age_0, init-value=0
        data-element=FD14_Point_Map_Cruising_Age_1, init-value=0
        data-element=FD14_Point_Map_Cruising_Age_{10..19}, init-value=0
        data-element=FD14_Point_Map_Cruising_Age_2, init-value=0
        data-element=FD14_Point_Map_Cruising_Age_{20..29}, init-value=0
        data-element=FD14_Point_Map_Cruising_Age_3, init-value=0
        data-element=FD14_Point_Map_Cruising_Age_{30..39}, init-value=0
        data-element=FD14_Point_Map_Cruising_Age_4, init-value=0
        data-element=FD14_Point_Map_Cruising_Age_{40..49}, init-value=0
        data-element=FD14_Point_Map_Cruising_Age_5, init-value=0
        data-element=FD14_Point_Map_Cruising_Age_{50..59}, init-value=0
        data-element=FD14_Point_Map_Cruising_Age_6, init-value=0
        data-element=FD14_Point_Map_Cruising_Age_{60..69}, init-value=0
        data-element=FD14_Point_Map_Cruising_Age_7, init-value=0
        data-element=FD14_Point_Map_Cruising_Age_{70..79}, init-value=0
        data-element=FD14_Point_Map_Cruising_Age_8, init-value=0
        data-element=FD14_Point_Map_Cruising_Age_{80..89}, init-value=0
        data-element=FD14_Point_Map_Cruising_Age_9, init-value=0
        data-element=FD14_Point_Map_Cruising_Age_{90..95}, init-value=0
        data-element=FD14_Point_Map_Height_0, init-value=0
        data-element=FD14_Point_Map_Height_1, init-value=0
        data-element=FD14_Point_Map_Height_{10..19}, init-value=0
        data-element=FD14_Point_Map_Height_2, init-value=0
        data-element=FD14_Point_Map_Height_{20..29}, init-value=0
        data-element=FD14_Point_Map_Height_3, init-value=0
        data-element=FD14_Point_Map_Height_{30..39}, init-value=0
        data-element=FD14_Point_Map_Height_4, init-value=0
        data-element=FD14_Point_Map_Height_{40..49}, init-value=0
        data-element=FD14_Point_Map_Height_5, init-value=0
        data-element=FD14_Point_Map_Height_{50..59}, init-value=0
        data-element=FD14_Point_Map_Height_6, init-value=0
        data-element=FD14_Point_Map_Height_{60..69}, init-value=0
        data-element=FD14_Point_Map_Height_7, init-value=0
        data-element=FD14_Point_Map_Height_{70..79}, init-value=0
        data-element=FD14_Point_Map_Height_8, init-value=0
        data-element=FD14_Point_Map_Height_{80..89}, init-value=0
        data-element=FD14_Point_Map_Height_9, init-value=0
        data-element=FD14_Point_Map_Height_{90..95}, init-value=0
        data-element=FD14_Point_Map_Reserved_0, init-value=0
        data-element=FD14_Point_Map_Reserved_1, init-value=0
        data-element=FD14_Point_Map_Reserved_{10..19}, init-value=0
        data-element=FD14_Point_Map_Reserved_2, init-value=0
        data-element=FD14_Point_Map_Reserved_{20..29}, init-value=0
        data-element=FD14_Point_Map_Reserved_3, init-value=0
        data-element=FD14_Point_Map_Reserved_{30..39}, init-value=0
        data-element=FD14_Point_Map_Reserved_4, init-value=0
        data-element=FD14_Point_Map_Reserved_{40..49}, init-value=0
        data-element=FD14_Point_Map_Reserved_5, init-value=0
        data-element=FD14_Point_Map_Reserved_{50..59}, init-value=0
        data-element=FD14_Point_Map_Reserved_6, init-value=0
        data-element=FD14_Point_Map_Reserved_{60..69}, init-value=0
        data-element=FD14_Point_Map_Reserved_7, init-value=0
        data-element=FD14_Point_Map_Reserved_{70..79}, init-value=0
        data-element=FD14_Point_Map_Reserved_8, init-value=0
        data-element=FD14_Point_Map_Reserved_{80..89}, init-value=0
        data-element=FD14_Point_Map_Reserved_9, init-value=0
        data-element=FD14_Point_Map_Reserved_{90..95}, init-value=0
        data-element=FD14_Point_Map_X_0, init-value=0
        data-element=FD14_Point_Map_X_1, init-value=0
        data-element=FD14_Point_Map_X_{10..19}, init-value=0
        data-element=FD14_Point_Map_X_2, init-value=0
        data-element=FD14_Point_Map_X_{20..29}, init-value=0
        data-element=FD14_Point_Map_X_3, init-value=0
        data-element=FD14_Point_Map_X_{30..39}, init-value=0
        data-element=FD14_Point_Map_X_4, init-value=0
        data-element=FD14_Point_Map_X_{40..49}, init-value=0
        data-element=FD14_Point_Map_X_5, init-value=0
        data-element=FD14_Point_Map_X_{50..59}, init-value=0
        data-element=FD14_Point_Map_X_6, init-value=0
        data-element=FD14_Point_Map_X_{60..69}, init-value=0
        data-element=FD14_Point_Map_X_7, init-value=0
        data-element=FD14_Point_Map_X_{70..79}, init-value=0
        data-element=FD14_Point_Map_X_8, init-value=0
        data-element=FD14_Point_Map_X_{80..89}, init-value=0
        data-element=FD14_Point_Map_X_9, init-value=0
        data-element=FD14_Point_Map_X_{90..95}, init-value=0
        data-element=FD14_Point_Map_Y_0, init-value=0
        data-element=FD14_Point_Map_Y_1, init-value=0
        data-element=FD14_Point_Map_Y_{10..19}, init-value=0
        data-element=FD14_Point_Map_Y_2, init-value=0
        data-element=FD14_Point_Map_Y_{20..29}, init-value=0
        data-element=FD14_Point_Map_Y_3, init-value=0
        data-element=FD14_Point_Map_Y_{30..39}, init-value=0
        data-element=FD14_Point_Map_Y_4, init-value=0
        data-element=FD14_Point_Map_Y_{40..49}, init-value=0
        data-element=FD14_Point_Map_Y_5, init-value=0
        data-element=FD14_Point_Map_Y_{50..59}, init-value=0
        data-element=FD14_Point_Map_Y_6, init-value=0
        data-element=FD14_Point_Map_Y_{60..69}, init-value=0
        data-element=FD14_Point_Map_Y_7, init-value=0
        data-element=FD14_Point_Map_Y_{70..79}, init-value=0
        data-element=FD14_Point_Map_Y_8, init-value=0
        data-element=FD14_Point_Map_Y_{80..89}, init-value=0
        data-element=FD14_Point_Map_Y_9, init-value=0
        data-element=FD14_Point_Map_Y_{90..95}, init-value=0
        data-element=FD14_Presentinfo, init-value=0
        data-element=FD14_Prev_DisplayedViewByAcore_e, init-value=0
        data-element=FD14_Prev_RequestedViewByHmiM_e, init-value=0
        data-element=FD14_Prev_SystemState_e, init-value=0
        data-element=FD14_Prev_TRG_Stat, init-value=0
        data-element=FD14_prndStatus_e, init-value=0
        data-element=FD14_REAR_CROSS_BTN_PRESSED_b, init-value=0
        data-element=FD14_REAR_TOP_BTN_PRESSED_b, init-value=0
        data-element=FD14_RearCrossButtonNoSelect_b, init-value=0
        data-element=FD14_RearCrossButtonSelect_b, init-value=0
        data-element=FD14_RearViewDynamics_b, init-value=0
        data-element=FD14_RecognitionInfo, init-value=0
        data-element=FD14_Reserved0_b, init-value=0
        data-element=FD14_Reserved08_b, init-value=0
        data-element=FD14_Reserved09_b, init-value=0
        data-element=FD14_Reserved1_b, init-value=0
        data-element=FD14_Reserved{10..13}_b, init-value=0
        data-element=FD14_Reserved2_b, init-value=0
        data-element=FD14_Reserved3_b, init-value=0
        data-element=FD14_revGear_e, init-value=0
        data-element=FD14_RightCam_NA_b, init-value=0
        data-element=FD14_RightDoorFrontClose_Icon_b, init-value=0
        data-element=FD14_RightDoorFrontOpen_Icon_b, init-value=0
        data-element=FD14_RightDoorRearClose_Icon_b, init-value=0
        data-element=FD14_RightDoorRearOpen_Icon_b, init-value=0
        data-element=FD14_RIL_Blockage, init-value=0
        data-element=FD14_RIL_comm_Fault, init-value=0
        data-element=FD14_RIL_CommUnknown, init-value=0
        data-element=FD14_RIL_hardware_Fault, init-value=0
        data-element=FD14_RIL_MinDistance, init-value=0
        data-element=FD14_RIL_overTemp_Fault, init-value=0
        data-element=FD14_RIR_Blockage, init-value=0
        data-element=FD14_RIR_comm_Fault, init-value=0
        data-element=FD14_RIR_CommUnknown, init-value=0
        data-element=FD14_RIR_hardware_Fault, init-value=0
        data-element=FD14_RIR_MinDistance, init-value=0
        data-element=FD14_RIR_overTemp_Fault, init-value=0
        data-element=FD14_ROL_Blockage, init-value=0
        data-element=FD14_ROL_comm_Fault, init-value=0
        data-element=FD14_ROL_CommUnknown, init-value=0
        data-element=FD14_ROL_hardware_Fault, init-value=0
        data-element=FD14_ROL_MinDistance, init-value=0
        data-element=FD14_ROL_overTemp_Fault, init-value=0
        data-element=FD14_Roll_f32_Current_Rear, init-value=0
        data-element=FD14_Roll_f32_Current_Right, init-value=0
        data-element=FD14_Roll_f32_EOL_Front, init-value=0
        data-element=FD14_Roll_f32_EOL_Left, init-value=0
        data-element=FD14_Roll_f32_EOL_Rear, init-value=0
        data-element=FD14_Roll_f32_EOL_Right, init-value=0
        data-element=FD14_Roll_f32_OC_Front, init-value=0
        data-element=FD14_Roll_f32_OC_Left, init-value=0
        data-element=FD14_Roll_f32_OC_Rear, init-value=0
        data-element=FD14_Roll_f32_OC_Right, init-value=0
        data-element=FD14_Roll_f32_SC_Front, init-value=0
        data-element=FD14_Roll_f32_SC_Left, init-value=0
        data-element=FD14_Roll_f32_SC_Rear, init-value=0
        data-element=FD14_Roll_f32_SC_Right, init-value=0
        data-element=FD14_ROR_Blockage, init-value=0
        data-element=FD14_ROR_comm_Fault, init-value=0
        data-element=FD14_ROR_CommUnknown, init-value=0
        data-element=FD14_ROR_hardware_Fault, init-value=0
        data-element=FD14_ROR_MinDistance, init-value=0
        data-element=FD14_ROR_overTemp_Fault, init-value=0
        data-element=FD14_RSL_Blockage, init-value=0
        data-element=FD14_RSL_comm_Fault, init-value=0
        data-element=FD14_RSL_CommUnknown, init-value=0
        data-element=FD14_RSL_hardware_Fault, init-value=0
        data-element=FD14_RSL_MinDistance, init-value=0
        data-element=FD14_RSL_overTemp_Fault, init-value=0
        data-element=FD14_RSR_Blockage, init-value=0
        data-element=FD14_RSR_comm_Fault, init-value=0
        data-element=FD14_RSR_CommUnknown, init-value=0
        data-element=FD14_RSR_hardware_Fault, init-value=0
        data-element=FD14_RSR_MinDistance, init-value=0
        data-element=FD14_RSR_overTemp_Fault, init-value=0
        data-element=FD14_RVCONLY_BTN_PRESSED_b, init-value=0
        data-element=FD14_SC_ModuleState_STM_Front, init-value=0
        data-element=FD14_SC_ModuleState_STM_Left, init-value=0
        data-element=FD14_SC_ModuleState_STM_Rear, init-value=0
        data-element=FD14_SC_ModuleState_STM_Right, init-value=0
        data-element=FD14_slotSide, init-value=0
        data-element=FD14_SnrDat_FIL_Dir1_cm, init-value=0
        data-element=FD14_SnrDat_FIL_Dir2_cm, init-value=0
        data-element=FD14_SnrDat_FIR_Dir1_cm, init-value=0
        data-element=FD14_SnrDat_FIR_Dir2_cm, init-value=0
        data-element=FD14_SnrDat_FOL_Dir1_cm, init-value=0
        data-element=FD14_SnrDat_FOL_Dir2_cm, init-value=0
        data-element=FD14_SnrDat_FOR_Dir1_cm, init-value=0
        data-element=FD14_SnrDat_FOR_Dir2_cm, init-value=0
        data-element=FD14_SnrDat_FSL_Dir1_cm, init-value=0
        data-element=FD14_SnrDat_FSL_Dir2_cm, init-value=0
        data-element=FD14_SnrDat_FSR_Dir1_cm, init-value=0
        data-element=FD14_SnrDat_FSR_Dir2_cm, init-value=0
        data-element=FD14_SnrDat_RIL_Dir1_cm, init-value=0
        data-element=FD14_SnrDat_RIL_Dir2_cm, init-value=0
        data-element=FD14_SnrDat_RIR_Dir1_cm, init-value=0
        data-element=FD14_SnrDat_RIR_Dir2_cm, init-value=0
        data-element=FD14_SnrDat_ROL_Dir1_cm, init-value=0
        data-element=FD14_SnrDat_ROL_Dir2_cm, init-value=0
        data-element=FD14_SnrDat_ROR_Dir1_cm, init-value=0
        data-element=FD14_SnrDat_ROR_Dir2_cm, init-value=0
        data-element=FD14_SnrDat_RSL_Dir1_cm, init-value=0
        data-element=FD14_SnrDat_RSL_Dir2_cm, init-value=0
        data-element=FD14_SnrDat_RSR_Dir1_cm, init-value=0
        data-element=FD14_SnrDat_RSR_Dir2_cm, init-value=0
        data-element=FD14_SnrDat_sFIL_Indir_FIR_cm, init-value=0
        data-element=FD14_SnrDat_sFIL_Indir_FOL_cm, init-value=0
        data-element=FD14_SnrDat_sFIR_Indir_FIL_cm, init-value=0
        data-element=FD14_SnrDat_sFIR_Indir_FOR_cm, init-value=0
        data-element=FD14_SnrDat_sFOL_Indir_FIL_cm, init-value=0
        data-element=FD14_SnrDat_sFOL_Indir_FSL_cm, init-value=0
        data-element=FD14_SnrDat_sFOR_Indir_FIR_cm, init-value=0
        data-element=FD14_SnrDat_sFOR_Indir_FSR_cm, init-value=0
        data-element=FD14_SnrDat_sFSL_Indir_FOL_cm, init-value=0
        data-element=FD14_SnrDat_sFSR_Indir_FOR_cm, init-value=0
        data-element=FD14_SnrDat_sRIL_Indir_RIR_cm, init-value=0
        data-element=FD14_SnrDat_sRIL_Indir_ROL_cm, init-value=0
        data-element=FD14_SnrDat_sRIR_Indir_RIL_cm, init-value=0
        data-element=FD14_SnrDat_sRIR_Indir_ROR_cm, init-value=0
        data-element=FD14_SnrDat_sROL_Indir_RIL_cm, init-value=0
        data-element=FD14_SnrDat_sROL_Indir_RSL_cm, init-value=0
        data-element=FD14_SnrDat_sROR_Indir_RIR_cm, init-value=0
        data-element=FD14_SnrDat_sROR_Indir_RSR_cm, init-value=0
        data-element=FD14_SnrDat_sRSL_Indir_ROL_cm, init-value=0
        data-element=FD14_SnrDat_sRSR_Indir_ROR_cm, init-value=0
        data-element=FD14_SnrMeasDataChecksum, init-value=0
        data-element=FD14_SoftBtn_Error_e, init-value=0
        data-element=FD14_SrvCamIndBaNok_b, init-value=0
        data-element=FD14_SrvCamIndBaNone_b, init-value=0
        data-element=FD14_SrvCamIndBaOk_b, init-value=0
        data-element=FD14_SrvCamIndBaPend_b, init-value=0
        data-element=FD14_SrvCamIndFrNok_b, init-value=0
        data-element=FD14_SrvCamIndFrNone_b, init-value=0
        data-element=FD14_SrvCamIndFrOk_b, init-value=0
        data-element=FD14_SrvCamIndFrPend_b, init-value=0
        data-element=FD14_SrvCamIndLeNok_b, init-value=0
        data-element=FD14_SrvCamIndLeNone_b, init-value=0
        data-element=FD14_SrvCamIndLeOk_b, init-value=0
        data-element=FD14_SrvCamIndLePend_b, init-value=0
        data-element=FD14_SrvCamIndRiNok_b, init-value=0
        data-element=FD14_SrvCamIndRiNone_b, init-value=0
        data-element=FD14_SrvCamIndRiOk_b, init-value=0
        data-element=FD14_SrvCamIndRiPend_b, init-value=0
        data-element=FD14_SrvChkIndCondNok_b, init-value=0
        data-element=FD14_SrvChkIndNok_b, init-value=0
        data-element=FD14_SrvChkIndOk_b, init-value=0
        data-element=FD14_SrvChkIndRun_b, init-value=0
        data-element=FD14_SrvLayout_b, init-value=0
        data-element=FD14_SrvPrgBar0Per_b, init-value=0
        data-element=FD14_SrvPrgBar100Per_b, init-value=0
        data-element=FD14_SrvPrgBar20Per_b, init-value=0
        data-element=FD14_SrvPrgBar40Per_b, init-value=0
        data-element=FD14_SrvPrgBar60Per_b, init-value=0
        data-element=FD14_SrvPrgBar80Per_b, init-value=0
        data-element=FD14_SrvSpOmIndNok_b, init-value=0
        data-element=FD14_SrvSpOmIndOk_b, init-value=0
        data-element=FD14_SrvStAngIndNok_b, init-value=0
        data-element=FD14_SrvStAngIndOk_b, init-value=0
        data-element=FD14_steeringWheelAngle_f32, init-value=0
        data-element=FD14_stFPAInfoToHMISlot{1..6}Valid, init-value=0
        data-element=FD14_stFPAInfoToVCLockedSlotFrntLeftX, init-value=0
        data-element=FD14_stFPAInfoToVCLockedSlotFrntLeftY, init-value=0
        data-element=FD14_stFPAInfoToVCLockedSlotID, init-value=0
        data-element=FD14_stFPAInfoToVCLockedSlotRearRghtX, init-value=0
        data-element=FD14_stFPAInfoToVCLockedSlotRearRghtY, init-value=0
        data-element=FD14_stFPAInfoToVCLockedSlotSide, init-value=0
        data-element=FD14_stFPAInfoToVCLockedSlotType, init-value=0
        data-element=FD14_stFPAInfoToVCLockedSlotValid, init-value=0
        data-element=FD14_stLeftObjectList{1..4}Valid, init-value=0
        data-element=FD14_STM_v_TRGAUTO_BTN_PRESSED_b, init-value=0
        data-element=FD14_STM_v_TRGLEFT_BTN_PRESSED_b, init-value=0
        data-element=FD14_STM_v_TRGRIGHT_BTN_PRESSED_b, init-value=0
        data-element=FD14_stnumPointsL, init-value=0
        data-element=FD14_stnumPointsR, init-value=0
        data-element=FD14_stPLDLockedSlotDataFrontLeftX, init-value=0
        data-element=FD14_stPLDLockedSlotDataFrontLeftY, init-value=0
        data-element=FD14_stPLDLockedSlotDataRearRightX, init-value=0
        data-element=FD14_stPLDLockedSlotDataRearRightY, init-value=0
        data-element=FD14_stPLDLockedSlotDataSlotID, init-value=0
        data-element=FD14_stPLDLockedSlotDataSlotSide, init-value=0
        data-element=FD14_stPLDLockedSlotDataSlotType, init-value=0
        data-element=FD14_stPLDLockedSlotDataSlotValid, init-value=0
        data-element=FD14_stPLDParkingSlot1DataSlotID, init-value=0
        data-element=FD14_stPLDParkingSlot1DataSlotSide, init-value=0
        data-element=FD14_stPLDParkingSlot1FrontLeftX, init-value=0
        data-element=FD14_stPLDParkingSlot1FrontLeftY, init-value=0
        data-element=FD14_stPLDParkingSlot1RearRightX, init-value=0
        data-element=FD14_stPLDParkingSlot1RearRightY, init-value=0
        data-element=FD14_stPLDParkingSlot1SlotType, init-value=0
        data-element=FD14_stPLDParkingSlot{1..3}SlotValid, init-value=0
        data-element=FD14_stPLDParkingSlot4DataSlotID, init-value=0
        data-element=FD14_stPLDParkingSlot4DataSlotSide, init-value=0
        data-element=FD14_stPLDParkingSlot4FrontLeftX, init-value=0
        data-element=FD14_stPLDParkingSlot4FrontLeftY, init-value=0
        data-element=FD14_stPLDParkingSlot4RearRightX, init-value=0
        data-element=FD14_stPLDParkingSlot4RearRightY, init-value=0
        data-element=FD14_stPLDParkingSlot4SlotType, init-value=0
        data-element=FD14_stPLDParkingSlot{4..6}SlotValid, init-value=0
        data-element=FD14_stRightObjectList{1..4}Valid, init-value=0
        data-element=FD14_stUSSLockedSlotDataFrontLeftX, init-value=0
        data-element=FD14_stUSSLockedSlotDataFrontLeftY, init-value=0
        data-element=FD14_stUSSLockedSlotDataRearRightX, init-value=0
        data-element=FD14_stUSSLockedSlotDataRearRightY, init-value=0
        data-element=FD14_stUSSLockedSlotDataSlotID, init-value=0
        data-element=FD14_stUSSLockedSlotDataSlotSide, init-value=0
        data-element=FD14_stUSSLockedSlotDataSlotType, init-value=0
        data-element=FD14_stUSSLockedSlotDataSlotValid, init-value=0
        data-element=FD14_stUSSParkingSlot1DataSlotID, init-value=0
        data-element=FD14_stUSSParkingSlot1DataSlotSide, init-value=0
        data-element=FD14_stUSSParkingSlot1FrontLeftX, init-value=0
        data-element=FD14_stUSSParkingSlot1FrontLeftY, init-value=0
        data-element=FD14_stUSSParkingSlot1RearRightX, init-value=0
        data-element=FD14_stUSSParkingSlot1RearRightY, init-value=0
        data-element=FD14_stUSSParkingSlot1SlotType, init-value=0
        data-element=FD14_stUSSParkingSlot{1..3}SlotValid, init-value=0
        data-element=FD14_stUSSParkingSlot4DataSlotSide, init-value=0
        data-element=FD14_stUSSParkingSlot4FrontLeftX, init-value=0
        data-element=FD14_stUSSParkingSlot4FrontLeftY, init-value=0
        data-element=FD14_stUSSParkingSlot4RearRightX, init-value=0
        data-element=FD14_stUSSParkingSlot4RearRightY, init-value=0
        data-element=FD14_stUSSParkingSlot4SlotType, init-value=0
        data-element=FD14_stUSSParkingSlot{4..6}SlotValid, init-value=0
        data-element=FD14_SVC_Delay_Feature_b, init-value=1
        data-element=FD14_SVC_Dynamic_Gridlines_Feature_b, init-value=1
        data-element=FD14_SVC_FFCV_Gridlines_Feature_b, init-value=1
        data-element=FD14_SVC_Static_Gridlines_Feature_b, init-value=1
        data-element=FD14_SystemMode, init-value=0
        data-element=FD14_SystemStatus, init-value=0
        data-element=FD14_TadAngle, init-value=0
        data-element=FD14_TADAngleRate, init-value=0
        data-element=FD14_TargetDetectLeftFront_Front_s8, init-value=0
        data-element=FD14_TargetDetectLeftFront_Left_s8, init-value=0
        data-element=FD14_TargetDetectLeftFront_Rear_s8, init-value=0
        data-element=FD14_TargetDetectLeftFront_Right_s8, init-value=0
        data-element=FD14_TargetDetectLeftRear_Front_s8, init-value=0
        data-element=FD14_TargetDetectLeftRear_Rear_s8, init-value=0
        data-element=FD14_TargetDetectLeftRear_Right_s8, init-value=0
        data-element=FD14_TargetDetectRightFront_Front_s8, init-value=0
        data-element=FD14_TargetDetectRightFront_Left_s8, init-value=0
        data-element=FD14_TargetDetectRightFront_Rear_s8, init-value=0
        data-element=FD14_TargetDetectRightFront_Right_s8, init-value=0
        data-element=FD14_TargetDetectRightRear_Front_s8, init-value=0
        data-element=FD14_TargetDetectRightRear_Left_s8, init-value=0
        data-element=FD14_TargetDetectRightRear_Rear_s8, init-value=0
        data-element=FD14_TargetDetectRightRear_Right_s8, init-value=0
        data-element=FD14_TargetInit_Front_s8, init-value=0
        data-element=FD14_TargetInit_Left_s8, init-value=0
        data-element=FD14_TargetInit_Rear_s8, init-value=0
        data-element=FD14_TargetInit_Right_s8, init-value=0
        data-element=FD14_TargetLimitFront_Front_s8, init-value=0
        data-element=FD14_TargetLimitFront_Left_s8, init-value=0
        data-element=FD14_TargetLimitFront_Rear_s8, init-value=0
        data-element=FD14_TargetLimitFront_Right_s8, init-value=0
        data-element=FD14_TargetLimitRear_Front_s8, init-value=0
        data-element=FD14_TargetLimitRear_Left_s8, init-value=0
        data-element=FD14_TargetLimitRear_Rear_s8, init-value=0
        data-element=FD14_TargetLimitRear_Right_s8, init-value=0
        data-element=FD14_tchScrnCoord_s_X_u16, init-value=0
        data-element=FD14_tchScrnCoord_s_Y_u16, init-value=0
        data-element=FD14_tchScrnStatus_e, init-value=0
        data-element=FD14_tgwDispStatus_e, init-value=0
        data-element=FD14_THAButtonGrey, init-value=0
        data-element=FD14_THAButtonSelectable, init-value=0
        data-element=FD14_THAConfirmButton, init-value=0
        data-element=FD14_THACouplerBulletIcon, init-value=0
        data-element=FD14_THAProgressBar, init-value=0
        data-element=FD14_THAStartButton, init-value=0
        data-element=FD14_THATriangleOverlay, init-value=0
        data-element=FD14_TimeStamp_SystemStatus, init-value=0
        data-element=FD14_TopFrontButtonNoSelect_b, init-value=0
        data-element=FD14_TopFrontButtonSelect_b, init-value=0
        data-element=FD14_TopRearButtonNoSelect_b, init-value=0
        data-element=FD14_TopRearButtonSelect_b, init-value=0
        data-element=FD14_TopVideoBlanked_b, init-value=1
        data-element=FD14_TopViewBlack_b, init-value=0
        data-element=FD14_TopViewFrontDynamics_b, init-value=0
        data-element=FD14_TopViewRearDynamics_b, init-value=0
        data-element=FD14_Total_lines_count, init-value=0
        data-element=FD14_Trailer_Recognition_Confidence, init-value=0
        data-element=FD14_Trailer_tracking_confidence, init-value=0
        data-element=FD14_trailerAngle, init-value=0
        data-element=FD14_TrailerAngleSign, init-value=0
        data-element=FD14_TrailerCalFailInfo, init-value=0
        data-element=FD14_trailerCalibrationCount, init-value=0
        data-element=FD14_trailerCalibrationDelay, init-value=0
        data-element=FD14_TrailerCalibrationStatus, init-value=0
        data-element=FD14_Trailercalinfo, init-value=2
        data-element=FD14_TrailerConnectionStatus, init-value=0
        data-element=FD14_TrailerWheelBase, init-value=0
        data-element=FD14_transEquipped_e, init-value=0
        data-element=FD14_TrscJackKnifeOrange, init-value=0
        data-element=FD14_TrscJackKnifeRed, init-value=0
        data-element=FD14_TrscOvl, init-value=0
        data-element=FD14_trscStat_e, init-value=0
        data-element=FD14_TrscStatus, init-value=0
        data-element=FD14_TrscTrailerRed, init-value=0
        data-element=FD14_Tstr_SD_FIL_DrvFreq, init-value=0
        data-element=FD14_Tstr_SD_FIL_EchoHeight_adc, init-value=0
        data-element=FD14_Tstr_SD_FIL_RingFreq, init-value=0
        data-element=FD14_Tstr_SD_FIL_Ringtime_us, init-value=0
        data-element=FD14_Tstr_SD_FIL_SensorBlkgClrCounter, init-value=0
        data-element=FD14_Tstr_SD_FIL_SensorBlkgSetCounter, init-value=0
        data-element=FD14_Tstr_SD_FIL_Unfiltered_DirDist1, init-value=0
        data-element=FD14_Tstr_SD_FIL_Unfiltered_DirDist2, init-value=0
        data-element=FD14_Tstr_SD_FIR_DrvFreq, init-value=0
        data-element=FD14_Tstr_SD_FIR_EchoHeight_adc, init-value=0
        data-element=FD14_Tstr_SD_FIR_RingFreq, init-value=0
        data-element=FD14_Tstr_SD_FIR_Ringtime_us, init-value=0
        data-element=FD14_Tstr_SD_FIR_SensorBlkgClrCounter, init-value=0
        data-element=FD14_Tstr_SD_FIR_SensorBlkgSetCounter, init-value=0
        data-element=FD14_Tstr_SD_FIR_Unfiltered_DirDist1, init-value=0
        data-element=FD14_Tstr_SD_FIR_Unfiltered_DirDist2, init-value=0
        data-element=FD14_Tstr_SD_FOL_DrvFreq, init-value=0
        data-element=FD14_Tstr_SD_FOL_EchoHeight_adc, init-value=0
        data-element=FD14_Tstr_SD_FOL_RingFreq, init-value=0
        data-element=FD14_Tstr_SD_FOL_Ringtime_us, init-value=0
        data-element=FD14_Tstr_SD_FOL_SensorBlkgClrCounter, init-value=0
        data-element=FD14_Tstr_SD_FOL_SensorBlkgSetCounter, init-value=0
        data-element=FD14_Tstr_SD_FOL_Unfiltered_DirDist1, init-value=0
        data-element=FD14_Tstr_SD_FOL_Unfiltered_DirDist2, init-value=0
        data-element=FD14_Tstr_SD_FOR_DrvFreq, init-value=0
        data-element=FD14_Tstr_SD_FOR_EchoHeight_adc, init-value=0
        data-element=FD14_Tstr_SD_FOR_RingFreq, init-value=0
        data-element=FD14_Tstr_SD_FOR_Ringtime_us, init-value=0
        data-element=FD14_Tstr_SD_FOR_SensorBlkgClrCounter, init-value=0
        data-element=FD14_Tstr_SD_FOR_SensorBlkgSetCounter, init-value=0
        data-element=FD14_Tstr_SD_FOR_Unfiltered_DirDist1, init-value=0
        data-element=FD14_Tstr_SD_FOR_Unfiltered_DirDist2, init-value=0
        data-element=FD14_Tstr_SD_FSL_DrvFreq, init-value=0
        data-element=FD14_Tstr_SD_FSL_EchoHeight_adc, init-value=0
        data-element=FD14_Tstr_SD_FSL_RingFreq, init-value=0
        data-element=FD14_Tstr_SD_FSL_Ringtime_us, init-value=0
        data-element=FD14_Tstr_SD_FSL_SensorBlkgClrCounter, init-value=0
        data-element=FD14_Tstr_SD_FSL_SensorBlkgSetCounter, init-value=0
        data-element=FD14_Tstr_SD_FSL_Unfiltered_DirDist1, init-value=0
        data-element=FD14_Tstr_SD_FSL_Unfiltered_DirDist2, init-value=0
        data-element=FD14_Tstr_SD_FSR_DrvFreq, init-value=0
        data-element=FD14_Tstr_SD_FSR_EchoHeight_adc, init-value=0
        data-element=FD14_Tstr_SD_FSR_RingFreq, init-value=0
        data-element=FD14_Tstr_SD_FSR_Ringtime_us, init-value=0
        data-element=FD14_Tstr_SD_FSR_SensorBlkgClrCounter, init-value=0
        data-element=FD14_Tstr_SD_FSR_SensorBlkgSetCounter, init-value=0
        data-element=FD14_Tstr_SD_FSR_Unfiltered_DirDist1, init-value=0
        data-element=FD14_Tstr_SD_FSR_Unfiltered_DirDist2, init-value=0
        data-element=FD14_Tstr_SD_RIL_DrvFreq, init-value=0
        data-element=FD14_Tstr_SD_RIL_EchoHeight_adc, init-value=0
        data-element=FD14_Tstr_SD_RIL_RingFreq, init-value=0
        data-element=FD14_Tstr_SD_RIL_Ringtime_us, init-value=0
        data-element=FD14_Tstr_SD_RIL_SensorBlkgClrCounter, init-value=0
        data-element=FD14_Tstr_SD_RIL_SensorBlkgSetCounter, init-value=0
        data-element=FD14_Tstr_SD_RIL_Unfiltered_DirDist1, init-value=0
        data-element=FD14_Tstr_SD_RIL_Unfiltered_DirDist2, init-value=0
        data-element=FD14_Tstr_SD_RIR_DrvFreq, init-value=0
        data-element=FD14_Tstr_SD_RIR_EchoHeight_adc, init-value=0
        data-element=FD14_Tstr_SD_RIR_RingFreq, init-value=0
        data-element=FD14_Tstr_SD_RIR_Ringtime_us, init-value=0
        data-element=FD14_Tstr_SD_RIR_SensorBlkgClrCounter, init-value=0
        data-element=FD14_Tstr_SD_RIR_SensorBlkgSetCounter, init-value=0
        data-element=FD14_Tstr_SD_RIR_Unfiltered_DirDist1, init-value=0
        data-element=FD14_Tstr_SD_RIR_Unfiltered_DirDist2, init-value=0
        data-element=FD14_Tstr_SD_ROL_DrvFreq, init-value=0
        data-element=FD14_Tstr_SD_ROL_EchoHeight_adc, init-value=0
        data-element=FD14_Tstr_SD_ROL_RingFreq, init-value=0
        data-element=FD14_Tstr_SD_ROL_Ringtime_us, init-value=0
        data-element=FD14_Tstr_SD_ROL_SensorBlkgClrCounter, init-value=0
        data-element=FD14_Tstr_SD_ROL_SensorBlkgSetCounter, init-value=0
        data-element=FD14_Tstr_SD_ROL_Unfiltered_DirDist1, init-value=0
        data-element=FD14_Tstr_SD_ROL_Unfiltered_DirDist2, init-value=0
        data-element=FD14_Tstr_SD_ROR_DrvFreq, init-value=0
        data-element=FD14_Tstr_SD_ROR_EchoHeight_adc, init-value=0
        data-element=FD14_Tstr_SD_ROR_RingFreq, init-value=0
        data-element=FD14_Tstr_SD_ROR_Ringtime_us, init-value=0
        data-element=FD14_Tstr_SD_ROR_SensorBlkgClrCounter, init-value=0
        data-element=FD14_Tstr_SD_ROR_SensorBlkgSetCounter, init-value=0
        data-element=FD14_Tstr_SD_ROR_Unfiltered_DirDist1, init-value=0
        data-element=FD14_Tstr_SD_ROR_Unfiltered_DirDist2, init-value=0
        data-element=FD14_Tstr_SD_RSL_DrvFreq, init-value=0
        data-element=FD14_Tstr_SD_RSL_EchoHeight_adc, init-value=0
        data-element=FD14_Tstr_SD_RSL_RingFreq, init-value=0
        data-element=FD14_Tstr_SD_RSL_Ringtime_us, init-value=0
        data-element=FD14_Tstr_SD_RSL_SensorBlkgClrCounter, init-value=0
        data-element=FD14_Tstr_SD_RSL_SensorBlkgSetCounter, init-value=0
        data-element=FD14_Tstr_SD_RSL_Unfiltered_DirDist1, init-value=0
        data-element=FD14_Tstr_SD_RSL_Unfiltered_DirDist2, init-value=0
        data-element=FD14_Tstr_SD_RSR_DrvFreq, init-value=0
        data-element=FD14_Tstr_SD_RSR_EchoHeight_adc, init-value=0
        data-element=FD14_Tstr_SD_RSR_RingFreq, init-value=0
        data-element=FD14_Tstr_SD_RSR_Ringtime_us, init-value=0
        data-element=FD14_Tstr_SD_RSR_SensorBlkgClrCounter, init-value=0
        data-element=FD14_Tstr_SD_RSR_SensorBlkgSetCounter, init-value=0
        data-element=FD14_Tstr_SD_RSR_Unfiltered_DirDist1, init-value=0
        data-element=FD14_Tstr_SD_RSR_Unfiltered_DirDist2, init-value=0
        data-element=FD14_turnaroundSubState, init-value=0
        data-element=FD14_USS_MPAZoneB{00..03}, init-value=0
        data-element=FD14_USS_MPAZoneF{00..03}, init-value=0
        data-element=FD14_ValidFeatures_Front_u32, init-value=0
        data-element=FD14_ValidFeatures_Left_u32, init-value=0
        data-element=FD14_ValidFeatures_Rear_u32, init-value=0
        data-element=FD14_ValidFeatures_Right_u32, init-value=0
        data-element=FD14_vehicleLine_e, init-value=0
        data-element=FD14_vehicleSpeed_f32, init-value=0
        data-element=FD14_View_Error_e, init-value=0
        data-element=FD14_X_BTN_PRESSED_b, init-value=0
        data-element=FD14_X_f32_Current_Rear, init-value=0
        data-element=FD14_X_f32_Current_Right, init-value=0
        data-element=FD14_X_f32_EOL_Front, init-value=0
        data-element=FD14_X_f32_EOL_Left, init-value=0
        data-element=FD14_X_f32_EOL_Rear, init-value=0
        data-element=FD14_X_f32_EOL_Right, init-value=0
        data-element=FD14_XIcon_b, init-value=0
        data-element=FD14_Y_f32_Current_Rear, init-value=0
        data-element=FD14_Y_f32_Current_Right, init-value=0
        data-element=FD14_Y_f32_EOL_Front, init-value=0
        data-element=FD14_Y_f32_EOL_Left, init-value=0
        data-element=FD14_Y_f32_EOL_Rear, init-value=0
        data-element=FD14_Y_f32_EOL_Right, init-value=0
        data-element=FD14_Yaw_f32_Current_Rear, init-value=0
        data-element=FD14_Yaw_f32_Current_Right, init-value=0
        data-element=FD14_Yaw_f32_EOL_Front, init-value=0
        data-element=FD14_Yaw_f32_EOL_Left, init-value=0
        data-element=FD14_Yaw_f32_EOL_Rear, init-value=0
        data-element=FD14_Yaw_f32_EOL_Right, init-value=0
        data-element=FD14_Yaw_f32_OC_Front, init-value=0
        data-element=FD14_Yaw_f32_OC_Left, init-value=0
        data-element=FD14_Yaw_f32_OC_Rear, init-value=0
        data-element=FD14_Yaw_f32_OC_Right, init-value=0
        data-element=FD14_Yaw_f32_SC_Front, init-value=0
        data-element=FD14_Yaw_f32_SC_Left, init-value=0
        data-element=FD14_Yaw_f32_SC_Rear, init-value=0
        data-element=FD14_Yaw_f32_SC_Right, init-value=0
        data-element=FD14_Z_f32_Current_Rear, init-value=0
        data-element=FD14_Z_f32_Current_Right, init-value=0
        data-element=FD14_Z_f32_EOL_Front, init-value=0
        data-element=FD14_Z_f32_EOL_Left, init-value=0
        data-element=FD14_Z_f32_EOL_Rear, init-value=0
        data-element=FD14_Z_f32_EOL_Right, init-value=0
        data-element=FD14_ZoomButtonDisable_b, init-value=0
        data-element=FD14_ZoomFactor_u8, init-value=0
        data-element=FD14_ZoomMinusIcon_b, init-value=0
        data-element=FD14_ZoomPlusIcon_b, init-value=0
    require port RpFromSwcFD02Tx: required-interface=IF_ToComFD02Tx
      required-com-specs:
        data-element=CurrentCanNMState_FD02_PAM, filter=data-filter-type=ALWAYS, init-value=0
        data-element=CurrentFailSts_FD02_PAM, filter=data-filter-type=ALWAYS, init-value=0
        data-element=DES_FD02_PAM, filter=data-filter-type=ALWAYS, init-value=0
        data-element=Digit_{01..11}_PAM, filter=data-filter-type=ALWAYS, init-value=0
        data-element=EOL_FD02_PAM, filter=data-filter-type=ALWAYS, init-value=0
        data-element=GenericFailSts_FD02_PAM, filter=data-filter-type=ALWAYS, init-value=0
        {data-element=N_PDU, filter=data-filter-type=ALWAYS, init-value=[rule-based-values={rule=FILL_UNTIL_END, rule-arguments=0}]}
        data-element=PreviousCanNMState_FD02_PAM, filter=data-filter-type=ALWAYS, init-value=0
        {data-element=StayActiveSource_FD02_PAM, filter=data-filter-type=ALWAYS, init-value=[rule-based-values={rule=FILL_UNTIL_END, rule-arguments=0}]}
        data-element=THA_EPB_Req, filter=data-filter-type=ALWAYS, init-value=0
        data-element=THA_Speed_Limit, filter=data-filter-type=ALWAYS, init-value=0
        data-element=THA_SpeedLimit_Req, filter=data-filter-type=ALWAYS, init-value=0
        data-element=THA_STAT, filter=data-filter-type=ALWAYS, init-value=0
        data-element=THA_SteeringDamping, filter=data-filter-type=ALWAYS, init-value=78.125
        data-element=THA_SteeringTorqueInfo, filter=data-filter-type=ALWAYS, init-value=0
        data-element=THA_SteeringTorqueReq, filter=data-filter-type=ALWAYS, init-value=0
        data-element=Trailer_Angle, filter=data-filter-type=ALWAYS, init-value=0
        data-element=Trailer_Angle_Sign, filter=data-filter-type=ALWAYS, init-value=0
        data-element=Trailer_Calibration, filter=data-filter-type=ALWAYS, init-value=0
        data-element=TrlrHitchLight_Cntrl, filter=data-filter-type=ALWAYS, init-value=0
        data-element=TRSC_PopupDisp_Info, filter=data-filter-type=ALWAYS, init-value=0
        data-element=TRSC_SpeedLimit_Req, filter=data-filter-type=ALWAYS, init-value=0
        data-element=TRSC_STAT, filter=data-filter-type=ALWAYS, init-value=1
        data-element=TRSC_SteeringDamping, filter=data-filter-type=ALWAYS, init-value=100
        data-element=TRSC_SteeringTorqueInfo, filter=data-filter-type=ALWAYS, init-value=0
        data-element=TRSC_SteeringTorqueReq, filter=data-filter-type=ALWAYS, init-value=0
        data-element=TRSC_VehicleStop_Req, filter=data-filter-type=ALWAYS, init-value=3
        data-element=TRSCMoreCamRQSts, filter=data-filter-type=ALWAYS, init-value=0
        data-element=WakeupSource_FD02_PAM, filter=data-filter-type=ALWAYS, init-value=0
        data-element=TRSC_PopupDisp_Info2, filter=data-filter-type=ALWAYS, init-value=0
    provide port PpToSwcFD02Tx: provided-interface=IF_ToSwcFD02Tx
      provided-com-specs:
        WakeupSource_FD02_PAM
        TRSCMoreCamRQSts
        TRSC_VehicleStop_Req
        TRSC_SteeringTorqueReq
        TRSC_SteeringTorqueInfo
        TRSC_SteeringDamping
        TRSC_STAT
        TRSC_SpeedLimit_Req
        TRSC_PopupDisp_Info
        TrlrHitchLight_Cntrl
        Trailer_Calibration
        Trailer_Angle_Sign
        Trailer_Angle
        THA_SteeringTorqueReq
        THA_SteeringTorqueInfo
        THA_SteeringDamping
        THA_STAT
        THA_SpeedLimit_Req
        THA_Speed_Limit
        THA_EPB_Req
        StayActiveSource_FD02_PAM
        PreviousCanNMState_FD02_PAM
        N_PDU
        GenericFailSts_FD02_PAM
        EOL_FD02_PAM
        Digit_11_PAM
        Digit_10_PAM
        Digit_09_PAM
        Digit_08_PAM
        Digit_07_PAM
        Digit_06_PAM
        Digit_05_PAM
        Digit_04_PAM
        Digit_03_PAM
        Digit_02_PAM
        Digit_01_PAM
        DES_FD02_PAM
        CurrentFailSts_FD02_PAM
        CurrentCanNMState_FD02_PAM
        data-element=TRSC_PopupDisp_Info2, init-value=0
    provide port PpToSwcFD14Tx: provided-interface=IF_ToSwcFD14Tx
      provided-com-specs:
        data-element=FD14_THA_EPB_Req, init-value=0
        data-element=FD14_THA_Speed_Limit, init-value=0
        data-element=FD14_THA_SpeedLimit_Req, init-value=0
        data-element=FD14_THA_STAT, init-value=0
        data-element=FD14_THA_SteeringDamping, init-value=100
        data-element=FD14_THA_SteeringTorqueInfo, init-value=1024
        data-element=FD14_THA_SteeringTorqueReq, init-value=0
        data-element=FD14_TRSC_SpeedLimit_Req, init-value=0
        data-element=FD14_TRSC_STAT, init-value=1
        data-element=FD14_TRSC_SteeringDamping, init-value=100
        data-element=FD14_TRSC_SteeringTorqueInfo, init-value=1024
        data-element=FD14_TRSC_SteeringTorqueReq, init-value=0
        data-element=FD14_TRSC_VehicleStop_Req, init-value=3
    54 x require port:
      RpCVPAMFDData: nonqueued-receiver-com-spec=data-element=IFOD_Outputs_CVPAMFDData_t, required-interface=IF_CVPAMFDData
      RpCVPAMFDData2: nonqueued-receiver-com-spec=data-element=LMD_Outputs_CVPAMFDData2_t, required-interface=IF_CVPAMFDData2
      RpDebCurrDispOverlay: nonqueued-receiver-com-spec=data-element=Debug_HMI_Curr_Displayed_Overlays, required-interface=IF_DebCurrDispOverlay
      RpDebCurrDispProxiCfg: nonqueued-receiver-com-spec=data-element=Debug_HMI_Curr_Displayed_ProxiConfig, required-interface=IF_DebCurrDispProxiCfg
      RpDebCurReqOverlay: nonqueued-receiver-com-spec=data-element=Debug_HMI_Curr_Requested_Overlays, required-interface=IF_DebCurReqOverlay
      RpDebCurrReqProxiCfg: nonqueued-receiver-com-spec=data-element=Debug_HMI_Curr_Requested_ProxiConfig, required-interface=IF_DebCurrReqProxiCfg
      RpDebHmiInput: nonqueued-receiver-com-spec=data-element=Debug_HMI_Input_Data_t, required-interface=IF_DebHmiInput
      RpDebHmiInternal: nonqueued-receiver-com-spec=data-element=Debug_HMI_Internal_Data_t, required-interface=IF_DebHmiInternal
      RpDebHmiTrailViews: nonqueued-receiver-com-spec=data-element=Debug_HMI_Trailer_Views_Data_t, required-interface=IF_DebHmiTrailViews
      RpDetInpTrsc: nonqueued-receiver-com-spec=data-element=Detection_Inputs_from_TRSC_t, required-interface=IF_PpDetInpTrsc
      RpDriveAssistStatOut: nonqueued-receiver-com-spec=data-element=TbAP_DriveAssistStatOut_t, required-interface=IF_DriveAssistStatOut
      RpFeatureOutputsTHA: nonqueued-receiver-com-spec=data-element=TbTHASmVc_FeatureOutputs_t, required-interface=IF_FeatureOutputsTHA
      RpFPAWarnOut: nonqueued-receiver-com-spec=data-element=TbAP_FPAWarnOut_t, required-interface=IF_FPAWarnOut
      RpIJobUSSObjOp: nonqueued-receiver-com-spec{data-element=IJobUSSObjectMapOutput_t, filter=data-filter-type=ALWAYS}, required-interface=IF_IJobUSSObjOp
      RpJobFPAData: nonqueued-receiver-com-spec=data-element=IJobFPAOutput_t, required-interface=IF_JobFPAData
      RpJobPLDData: nonqueued-receiver-com-spec=data-element=IJobPLDOutput_t, required-interface=IF_JobPLDData
      RpJobTHADetOutput: nonqueued-receiver-com-spec=data-element=JobTHADetOutput_t, required-interface=IF_JobTHADetOutput
      RpLMDLaneOp: nonqueued-receiver-com-spec=data-element=LMD_Lane_Outputs_s, required-interface=IF_LMDLaneOp
      RpNFCDOutput: nonqueued-receiver-com-spec{data-element=NFCD_Output, filter=data-filter-type=ALWAYS}, required-interface=IF_NFCDOutput
      RpNVMSignMgr: nonqueued-receiver-com-spec{data-element=NVMSignalManager_t, filter=data-filter-type=ALWAYS}, required-interface=IF_NVMSignMgr
      RpPAStateOut: nonqueued-receiver-com-spec=data-element=TbAP_PAStateOut_t, required-interface=IF_PAStateOut
      RpPointDistOpBuff: nonqueued-receiver-com-spec=data-element=US_S_PointDistOutputBuff_t, required-interface=IF_PointDistOpBuff
      RpRPAWarnOut: nonqueued-receiver-com-spec=data-element=TbAP_RPAWarnOut_t, required-interface=IF_RPAWarnOut
      RpScreenRequest: nonqueued-receiver-com-spec=data-element=ScreenRequest_t, required-interface=IF_ScreenRequest
      RpSMDAInternal: nonqueued-receiver-com-spec=data-element=TbAP_SMDAInternalOut_t, required-interface=IF_SMDAInternal
      RpSR_State_MCU2: required-interface=R_SSM_2_State_SR
        required-com-specs:
          data-element=State_2_0, filter=data-filter-type=ALWAYS, init-value=fields=[CoreStatus:0, LocalAppStatus:20 x 0]
          data-element=State_2_1, filter=data-filter-type=ALWAYS, init-value=fields=[CoreStatus:0, LocalAppStatus:20 x 0]
      RpSVSNVMData: nonqueued-receiver-com-spec{data-element=SVS_NVMData_t, filter=data-filter-type=ALWAYS}, required-interface=IF_SVSNVMData
      RpSvsToTHA: nonqueued-receiver-com-spec=data-element=SvsToTHA_t, required-interface=IF_SvsToTHA
      RpSVStoTRSC: nonqueued-receiver-com-spec=data-element=SVStoTRSC_t, required-interface=IF_SVStoTRSC
      RpSvsToVCAN: nonqueued-receiver-com-spec=data-element=SvsToVCAN_t, required-interface=IF_SvsToVCAN
      RpTbAPDebugOut: nonqueued-receiver-com-spec=data-element=TbAP_DebugOut, required-interface=IF_TbAPDebugOut
      RpTbAPSMPAOut: nonqueued-receiver-com-spec=data-element=TbAP_SMPAInternalOut_t, required-interface=IF_TbAPSMPAOut
      RpTbFAArbiterOutput: nonqueued-receiver-com-spec{data-element=TbFA_ArbiterOutput_t, filter=data-filter-type=ALWAYS}, required-interface=IF_TbFAArbiterOutput
      RpTrailerDetectOP: nonqueued-receiver-com-spec=data-element=TrailerDetection_Output_DID_t, required-interface=IF_TrailerDetectOP
      RpTRSC: nonqueued-receiver-com-spec=data-element=ME_VehOut_TRSC_t, required-interface=IF_TRSC
      RpTrscSmvctoSvs: nonqueued-receiver-com-spec=data-element=TRSCSMVCtoSVS_t, required-interface=IF_TrscSmvctoSvs
      RpTrscToDiag: nonqueued-receiver-com-spec=data-element=TRSCtoDiagMgr_t, required-interface=IF_TrscToDiag
      RpTrscTrlrDet: nonqueued-receiver-com-spec=data-element=TRSC_Inputs_from_TrailerDetection_t, required-interface=IF_TrscTrlrDet
      RpUSSBlockageBit: nonqueued-receiver-com-spec=data-element=US_S_BlockageBit_t, required-interface=IF_USSBlockageBit
      RpUssDataCollection: nonqueued-receiver-com-spec=data-element=US_S_USSDataCollectionData_t, required-interface=IF_UssDataCollection
      RpUSSErrorDiagData: nonqueued-receiver-com-spec{data-element=US_S_USSErrorDiagData_t, filter=data-filter-type=ALWAYS}, required-interface=IF_USSErrorDiagData
      RpUssPointMapGrp: nonqueued-receiver-com-spec=data-element=US_S_PointMapGroup_t, required-interface=IF_UssPointMapGrp
      RpUssZoneInfo: nonqueued-receiver-com-spec=data-element=US_S_ZoneInfo_t, required-interface=IF_UssZoneInfo
      RpVCActuatorOut: nonqueued-receiver-com-spec=data-element=TbAP_VCActuatorOut_t, required-interface=IF_VCActuatorOut
      RpVCState: nonqueued-receiver-com-spec=data-element=TbAP_VCStateOut_t, required-interface=IF_VCState
      RpAPSMPAOut: nonqueued-receiver-com-spec=data-element=TbAP_APSMPAOut_t, required-interface=IF_APSMPAOut
      RpCan14DbgRoutineState: nonqueued-receiver-com-spec{data-element=Can14DbgRoutine, filter=data-filter-type=ALWAYS, init-value=0}, required-interface=IF_Can14DbgRoutine
      RpE2EServices: required-com-specs=[ME_E2E_Check, ME_E2E_Protect], required-interface=IF_E2EServices
      RpTRSCSMVCtoDebug: nonqueued-receiver-com-spec{data-element=TRSCSMVCtoDebugCAN_t, filter=data-filter-type=ALWAYS}, required-interface=IF_TRSCSMVCtoDebug
      RpUsCsmStatCngRsn: nonqueued-receiver-com-spec{data-element=US_S_CsmStateChangeReason_Type, filter=data-filter-type=ALWAYS, init-value=fields=[CsmStateCurrent:0, CsmStatePreviuos:0, CsmLocalModuleId:0, CsmLocalModuleInstanceId:0, CsmLocalErrOrEventId:0, CsmLocalErrOrEventState:0]}, required-interface=IF_UsCsmStatCngRsn
      RpUSSPeriodDiagData: nonqueued-receiver-com-spec{data-element=US_S_USSPeriodDiagData_t, filter=data-filter-type=ALWAYS}, required-interface=IF_PpUSSPeriodDiagData
      RpUssDebugMsg: nonqueued-receiver-com-spec{data-element=US_S_DebugMsg_t, filter=data-filter-type=ALWAYS}, required-interface=IF_UssDebugMsg
      RpFID_Output_QM: nonqueued-receiver-com-spec{data-element=FID_QM, filter=data-filter-type=ALWAYS}, required-interface=P_FID_Output_QM_SR
      RpBusOffIndication: nonqueued-receiver-com-spec{data-element=V_BusOffIndicationFlagRte_u8, filter=data-filter-type=ALWAYS}, required-interface=IF_BusOffIndication
